VERSION ""

NS_ :

BS_:

BU_: AFC TeampoEVB TDA4VE AutoBox HMI_Simulation
VAL_TABLE_ work_mode 2 " value '0x2'  direct echoes" 1 "value '0x1'  cross echoes " 0 "value '0x0'  off " ;

BO_ 3221225472 VECTOR__INDEPENDENT_SIG_MSG: 0 Vector__XXX
 SG_ AVM_Status_Flag : 0|2@0+ (1,0) [0|3] "" Vector__XXX
 SG_ AVM_Show_Flag : 0|2@0+ (1,0) [0|3] "" Vector__XXX
 SG_ USS_RR_RRM_Dis_Valid : 0|1@0+ (1,0) [0|1] "" Vector__XXX
 SG_ USS_RR_RRM_Dis : 0|9@0+ (0.02,0) [0|10.22] "m" Vector__XXX
 SG_ USS_RRM_RR_Dis_Valid : 0|1@0+ (1,0) [0|1] "" Vector__XXX
 SG_ USS_RRM_RR_Dis : 0|9@0+ (0.02,0) [0|10.22] "m" Vector__XXX
 SG_ USS_RRM_RLM_Dis_Valid : 0|1@0+ (1,0) [0|1] "" Vector__XXX
 SG_ USS_RRM_RLM_Dis : 0|9@0+ (0.02,0) [0|10.22] "m" Vector__XXX
 SG_ USS_RLM_RRM_Dis_Valid : 0|1@0+ (1,0) [0|1] "" Vector__XXX
 SG_ USS_RLM_RRM_Dis : 0|9@0+ (0.02,0) [0|10.22] "m" Vector__XXX
 SG_ USS_RLM_RL_Dis_Valid : 0|1@0+ (1,0) [0|1] "" Vector__XXX
 SG_ USS_RLM_RL_Dis : 0|9@0+ (0.02,0) [0|10.22] "m" Vector__XXX
 SG_ USS_RL_RLM_Dis_Valid : 0|1@0+ (1,0) [0|1] "" Vector__XXX
 SG_ USS_RL_RLM_Dis : 0|9@0+ (0.02,0) [0|10.22] "m" Vector__XXX

BO_ 776 P_USS_SEN8_ADV_TR: 1 Vector__XXX
 SG_ uss8_TR : 7|8@0+ (1,0) [0|3] "" Vector__XXX

BO_ 775 P_USS_SEN7_ADV_TR: 1 Vector__XXX
 SG_ uss7_TR : 7|8@0+ (1,0) [0|3] "" Vector__XXX

BO_ 774 P_USS_SEN6_ADV_TR: 1 Vector__XXX
 SG_ uss6_TR : 7|8@0+ (1,0) [0|3] "" Vector__XXX

BO_ 773 P_USS_SEN5_ADV_TR: 1 Vector__XXX
 SG_ uss5_TR : 7|8@0+ (1,0) [0|3] "" Vector__XXX

BO_ 772 P_USS_SEN4_ADV_TR: 1 Vector__XXX
 SG_ uss4_TR : 7|8@0+ (1,0) [0|3] "" Vector__XXX

BO_ 771 P_USS_SEN3_ADV_TR: 1 Vector__XXX
 SG_ uss3_TR : 7|8@0+ (1,0) [0|3] "" Vector__XXX

BO_ 770 P_USS_SEN2_ADV_TR: 1 Vector__XXX
 SG_ uss2_TR : 7|8@0+ (1,0) [0|3] "" Vector__XXX

BO_ 769 P_USS_SEN1_ADV_TR: 1 Vector__XXX
 SG_ uss1_TR : 7|8@0+ (1,0) [0|3] "" Vector__XXX

BO_ 1360 P_USS_SEN8_ADV_A: 8 Vector__XXX
 SG_ USS_SEN8_BRC20_HEIGHTFILT : 39|16@0+ (1,0) [0|65535] "" Vector__XXX
 SG_ USS_SEN8_BRC20_DISTANCE : 55|9@0+ (0.02,0) [0|10.22] "m" Vector__XXX
 SG_ USS_SEN8_BRC20_CONFLEVEL : 62|4@0+ (1,0) [0|15] "" Vector__XXX
 SG_ USS_SEN8_BRC19_HEIGHTFILT : 7|16@0+ (1,0) [0|65535] "" Vector__XXX
 SG_ USS_SEN8_BRC19_DISTANCE : 23|9@0+ (0.02,0) [0|10.22] "m" Vector__XXX
 SG_ USS_SEN8_BRC19_CONFLEVEL : 30|4@0+ (1,0) [0|15] "" Vector__XXX

BO_ 1359 P_USS_SEN8_ADV_9: 8 Vector__XXX
 SG_ USS_SEN8_BRC18_HEIGHTFILT : 39|16@0+ (1,0) [0|65535] "" Vector__XXX
 SG_ USS_SEN8_BRC18_DISTANCE : 55|9@0+ (0.02,0) [0|10.22] "m" Vector__XXX
 SG_ USS_SEN8_BRC18_CONFLEVEL : 62|4@0+ (1,0) [0|15] "" Vector__XXX
 SG_ USS_SEN8_BRC17_HEIGHTFILT : 7|16@0+ (1,0) [0|65535] "" Vector__XXX
 SG_ USS_SEN8_BRC17_DISTANCE : 23|9@0+ (0.02,0) [0|10.22] "m" Vector__XXX
 SG_ USS_SEN8_BRC17_CONFLEVEL : 30|4@0+ (1,0) [0|15] "" Vector__XXX

BO_ 1358 P_USS_SEN8_ADV_8: 8 Vector__XXX
 SG_ USS_SEN8_BRC16_HEIGHTFILT : 39|16@0+ (1,0) [0|65535] "" Vector__XXX
 SG_ USS_SEN8_BRC16_DISTANCE : 55|9@0+ (0.02,0) [0|10.22] "m" Vector__XXX
 SG_ USS_SEN8_BRC16_CONFLEVEL : 62|4@0+ (1,0) [0|15] "" Vector__XXX
 SG_ USS_SEN8_BRC15_HEIGHTFILT : 7|16@0+ (1,0) [0|65535] "" Vector__XXX
 SG_ USS_SEN8_BRC15_DISTANCE : 23|9@0+ (0.02,0) [0|10.22] "m" Vector__XXX
 SG_ USS_SEN8_BRC15_CONFLEVEL : 30|4@0+ (1,0) [0|15] "" Vector__XXX

BO_ 1357 P_USS_SEN8_ADV_7: 8 Vector__XXX
 SG_ USS_SEN8_BRC14_HEIGHTFILT : 39|16@0+ (1,0) [0|65535] "" Vector__XXX
 SG_ USS_SEN8_BRC14_DISTANCE : 55|9@0+ (0.02,0) [0|10.22] "m" Vector__XXX
 SG_ USS_SEN8_BRC14_CONFLEVEL : 62|4@0+ (1,0) [0|15] "" Vector__XXX
 SG_ USS_SEN8_BRC13_HEIGHTFILT : 7|16@0+ (1,0) [0|65535] "" Vector__XXX
 SG_ USS_SEN8_BRC13_DISTANCE : 23|9@0+ (0.02,0) [0|10.22] "m" Vector__XXX
 SG_ USS_SEN8_BRC13_CONFLEVEL : 30|4@0+ (1,0) [0|15] "" Vector__XXX

BO_ 1356 P_USS_SEN8_ADV_6: 8 Vector__XXX
 SG_ USS_SEN8_BRC12_HEIGHTFILT : 39|16@0+ (1,0) [0|65535] "" Vector__XXX
 SG_ USS_SEN8_BRC12_DISTANCE : 55|9@0+ (0.02,0) [0|10.22] "m" Vector__XXX
 SG_ USS_SEN8_BRC12_CONFLEVEL : 62|4@0+ (1,0) [0|15] "" Vector__XXX
 SG_ USS_SEN8_BRC11_HEIGHTFILT : 7|16@0+ (1,0) [0|65535] "" Vector__XXX
 SG_ USS_SEN8_BRC11_DISTANCE : 23|9@0+ (0.02,0) [0|10.22] "m" Vector__XXX
 SG_ USS_SEN8_BRC11_CONFLEVEL : 30|4@0+ (1,0) [0|15] "" Vector__XXX

BO_ 1355 P_USS_SEN8_ADV_5: 8 Vector__XXX
 SG_ USS_SEN8_BRC10_HEIGHTFILT : 39|16@0+ (1,0) [0|65535] "" Vector__XXX
 SG_ USS_SEN8_BRC10_DISTANCE : 55|9@0+ (0.02,0) [0|10.22] "m" Vector__XXX
 SG_ USS_SEN8_BRC10_CONFLEVEL : 62|4@0+ (1,0) [0|15] "" Vector__XXX
 SG_ USS_SEN8_BRC9_HEIGHTFILT : 7|16@0+ (1,0) [0|65535] "" Vector__XXX
 SG_ USS_SEN8_BRC9_DISTANCE : 23|9@0+ (0.02,0) [0|10.22] "m" Vector__XXX
 SG_ USS_SEN8_BRC9_CONFLEVEL : 30|4@0+ (1,0) [0|15] "" Vector__XXX

BO_ 1354 P_USS_SEN8_ADV_4: 8 Vector__XXX
 SG_ USS_SEN8_BRC8_HEIGHTFILT : 39|16@0+ (1,0) [0|65535] "" Vector__XXX
 SG_ USS_SEN8_BRC8_DISTANCE : 55|9@0+ (0.02,0) [0|10.22] "m" Vector__XXX
 SG_ USS_SEN8_BRC8_CONFLEVEL : 62|4@0+ (1,0) [0|15] "" Vector__XXX
 SG_ USS_SEN8_BRC7_HEIGHTFILT : 7|16@0+ (1,0) [0|65535] "" Vector__XXX
 SG_ USS_SEN8_BRC7_DISTANCE : 23|9@0+ (0.02,0) [0|10.22] "m" Vector__XXX
 SG_ USS_SEN8_BRC7_CONFLEVEL : 30|4@0+ (1,0) [0|15] "" Vector__XXX

BO_ 1353 P_USS_SEN8_ADV_3: 8 Vector__XXX
 SG_ USS_SEN8_BRC6_HEIGHTFILT : 39|16@0+ (1,0) [0|65535] "" Vector__XXX
 SG_ USS_SEN8_BRC6_DISTANCE : 55|9@0+ (0.02,0) [0|10.22] "m" Vector__XXX
 SG_ USS_SEN8_BRC6_CONFLEVEL : 62|4@0+ (1,0) [0|15] "" Vector__XXX
 SG_ USS_SEN8_BRC5_HEIGHTFILT : 7|16@0+ (1,0) [0|65535] "" Vector__XXX
 SG_ USS_SEN8_BRC5_DISTANCE : 23|9@0+ (0.02,0) [0|10.22] "m" Vector__XXX
 SG_ USS_SEN8_BRC5_CONFLEVEL : 30|4@0+ (1,0) [0|15] "" Vector__XXX

BO_ 1352 P_USS_SEN8_ADV_2: 8 Vector__XXX
 SG_ USS_SEN8_BRC4_HEIGHTFILT : 39|16@0+ (1,0) [0|65535] "" Vector__XXX
 SG_ USS_SEN8_BRC4_DISTANCE : 55|9@0+ (0.02,0) [0|10.22] "m" Vector__XXX
 SG_ USS_SEN8_BRC4_CONFLEVEL : 62|4@0+ (1,0) [0|15] "" Vector__XXX
 SG_ USS_SEN8_BRC3_HEIGHTFILT : 7|16@0+ (1,0) [0|65535] "" Vector__XXX
 SG_ USS_SEN8_BRC3_DISTANCE : 23|9@0+ (0.02,0) [0|10.22] "m" Vector__XXX
 SG_ USS_SEN8_BRC3_CONFLEVEL : 30|4@0+ (1,0) [0|15] "" Vector__XXX

BO_ 1351 P_USS_SEN8_ADV_1: 8 Vector__XXX
 SG_ USS_SEN8_BRC2_HEIGHTFILT : 39|16@0+ (1,0) [0|65535] "" Vector__XXX
 SG_ USS_SEN8_BRC2_DISTANCE : 55|9@0+ (0.02,0) [0|10.22] "m" Vector__XXX
 SG_ USS_SEN8_BRC2_CONFLEVEL : 62|4@0+ (1,0) [0|15] "" Vector__XXX
 SG_ USS_SEN8_BRC1_HEIGHTFILT : 7|16@0+ (1,0) [0|65535] "" Vector__XXX
 SG_ USS_SEN8_BRC1_DISTANCE : 23|9@0+ (0.02,0) [0|10.22] "m" Vector__XXX
 SG_ USS_SEN8_BRC1_CONFLEVEL : 30|4@0+ (1,0) [0|15] "" Vector__XXX

BO_ 1350 P_USS_SEN7_ADV_A: 8 Vector__XXX
 SG_ USS_SEN7_BRC20_HEIGHTFILT : 39|16@0+ (1,0) [0|65535] "" Vector__XXX
 SG_ USS_SEN7_BRC20_DISTANCE : 55|9@0+ (0.02,0) [0|10.22] "m" Vector__XXX
 SG_ USS_SEN7_BRC20_CONFLEVEL : 62|4@0+ (1,0) [0|15] "" Vector__XXX
 SG_ USS_SEN7_BRC19_HEIGHTFILT : 7|16@0+ (1,0) [0|65535] "" Vector__XXX
 SG_ USS_SEN7_BRC19_DISTANCE : 23|9@0+ (0.02,0) [0|10.22] "m" Vector__XXX
 SG_ USS_SEN7_BRC19_CONFLEVEL : 30|4@0+ (1,0) [0|15] "" Vector__XXX

BO_ 1349 P_USS_SEN7_ADV_9: 8 Vector__XXX
 SG_ USS_SEN7_BRC18_HEIGHTFILT : 39|16@0+ (1,0) [0|65535] "" Vector__XXX
 SG_ USS_SEN7_BRC18_DISTANCE : 55|9@0+ (0.02,0) [0|10.22] "m" Vector__XXX
 SG_ USS_SEN7_BRC18_CONFLEVEL : 62|4@0+ (1,0) [0|15] "" Vector__XXX
 SG_ USS_SEN7_BRC17_HEIGHTFILT : 7|16@0+ (1,0) [0|65535] "" Vector__XXX
 SG_ USS_SEN7_BRC17_DISTANCE : 23|9@0+ (0.02,0) [0|10.22] "m" Vector__XXX
 SG_ USS_SEN7_BRC17_CONFLEVEL : 30|4@0+ (1,0) [0|15] "" Vector__XXX

BO_ 1348 P_USS_SEN7_ADV_8: 8 Vector__XXX
 SG_ USS_SEN7_BRC16_HEIGHTFILT : 39|16@0+ (1,0) [0|65535] "" Vector__XXX
 SG_ USS_SEN7_BRC16_DISTANCE : 55|9@0+ (0.02,0) [0|10.22] "m" Vector__XXX
 SG_ USS_SEN7_BRC16_CONFLEVEL : 62|4@0+ (1,0) [0|15] "" Vector__XXX
 SG_ USS_SEN7_BRC15_HEIGHTFILT : 7|16@0+ (1,0) [0|65535] "" Vector__XXX
 SG_ USS_SEN7_BRC15_DISTANCE : 23|9@0+ (0.02,0) [0|10.22] "m" Vector__XXX
 SG_ USS_SEN7_BRC15_CONFLEVEL : 30|4@0+ (1,0) [0|15] "" Vector__XXX

BO_ 1347 P_USS_SEN7_ADV_7: 8 Vector__XXX
 SG_ USS_SEN7_BRC14_HEIGHTFILT : 39|16@0+ (1,0) [0|65535] "" Vector__XXX
 SG_ USS_SEN7_BRC14_DISTANCE : 55|9@0+ (0.02,0) [0|10.22] "m" Vector__XXX
 SG_ USS_SEN7_BRC14_CONFLEVEL : 62|4@0+ (1,0) [0|15] "" Vector__XXX
 SG_ USS_SEN7_BRC13_HEIGHTFILT : 7|16@0+ (1,0) [0|65535] "" Vector__XXX
 SG_ USS_SEN7_BRC13_DISTANCE : 23|9@0+ (0.02,0) [0|10.22] "m" Vector__XXX
 SG_ USS_SEN7_BRC13_CONFLEVEL : 30|4@0+ (1,0) [0|15] "" Vector__XXX

BO_ 1346 P_USS_SEN7_ADV_6: 8 Vector__XXX
 SG_ USS_SEN7_BRC12_HEIGHTFILT : 39|16@0+ (1,0) [0|65535] "" Vector__XXX
 SG_ USS_SEN7_BRC12_DISTANCE : 55|9@0+ (0.02,0) [0|10.22] "m" Vector__XXX
 SG_ USS_SEN7_BRC12_CONFLEVEL : 62|4@0+ (1,0) [0|15] "" Vector__XXX
 SG_ USS_SEN7_BRC11_HEIGHTFILT : 7|16@0+ (1,0) [0|65535] "" Vector__XXX
 SG_ USS_SEN7_BRC11_DISTANCE : 23|9@0+ (0.02,0) [0|10.22] "m" Vector__XXX
 SG_ USS_SEN7_BRC11_CONFLEVEL : 30|4@0+ (1,0) [0|15] "" Vector__XXX

BO_ 1345 P_USS_SEN7_ADV_5: 8 Vector__XXX
 SG_ USS_SEN7_BRC10_HEIGHTFILT : 39|16@0+ (1,0) [0|65535] "" Vector__XXX
 SG_ USS_SEN7_BRC10_DISTANCE : 55|9@0+ (0.02,0) [0|10.22] "m" Vector__XXX
 SG_ USS_SEN7_BRC10_CONFLEVEL : 62|4@0+ (1,0) [0|15] "" Vector__XXX
 SG_ USS_SEN7_BRC9_HEIGHTFILT : 7|16@0+ (1,0) [0|65535] "" Vector__XXX
 SG_ USS_SEN7_BRC9_DISTANCE : 23|9@0+ (0.02,0) [0|10.22] "m" Vector__XXX
 SG_ USS_SEN7_BRC9_CONFLEVEL : 30|4@0+ (1,0) [0|15] "" Vector__XXX

BO_ 1344 P_USS_SEN7_ADV_4: 8 Vector__XXX
 SG_ USS_SEN7_BRC8_HEIGHTFILT : 39|16@0+ (1,0) [0|65535] "" Vector__XXX
 SG_ USS_SEN7_BRC8_DISTANCE : 55|9@0+ (0.02,0) [0|10.22] "m" Vector__XXX
 SG_ USS_SEN7_BRC8_CONFLEVEL : 62|4@0+ (1,0) [0|15] "" Vector__XXX
 SG_ USS_SEN7_BRC7_HEIGHTFILT : 7|16@0+ (1,0) [0|65535] "" Vector__XXX
 SG_ USS_SEN7_BRC7_DISTANCE : 23|9@0+ (0.02,0) [0|10.22] "m" Vector__XXX
 SG_ USS_SEN7_BRC7_CONFLEVEL : 30|4@0+ (1,0) [0|15] "" Vector__XXX

BO_ 1343 P_USS_SEN7_ADV_3: 8 Vector__XXX
 SG_ USS_SEN7_BRC6_HEIGHTFILT : 39|16@0+ (1,0) [0|65535] "" Vector__XXX
 SG_ USS_SEN7_BRC6_DISTANCE : 55|9@0+ (0.02,0) [0|10.22] "m" Vector__XXX
 SG_ USS_SEN7_BRC6_CONFLEVEL : 62|4@0+ (1,0) [0|15] "" Vector__XXX
 SG_ USS_SEN7_BRC5_HEIGHTFILT : 7|16@0+ (1,0) [0|65535] "" Vector__XXX
 SG_ USS_SEN7_BRC5_DISTANCE : 23|9@0+ (0.02,0) [0|10.22] "m" Vector__XXX
 SG_ USS_SEN7_BRC5_CONFLEVEL : 30|4@0+ (1,0) [0|15] "" Vector__XXX

BO_ 1342 P_USS_SEN7_ADV_2: 8 Vector__XXX
 SG_ USS_SEN7_BRC4_HEIGHTFILT : 39|16@0+ (1,0) [0|65535] "" Vector__XXX
 SG_ USS_SEN7_BRC4_DISTANCE : 55|9@0+ (0.02,0) [0|10.22] "m" Vector__XXX
 SG_ USS_SEN7_BRC4_CONFLEVEL : 62|4@0+ (1,0) [0|15] "" Vector__XXX
 SG_ USS_SEN7_BRC3_HEIGHTFILT : 7|16@0+ (1,0) [0|65535] "" Vector__XXX
 SG_ USS_SEN7_BRC3_DISTANCE : 23|9@0+ (0.02,0) [0|10.22] "m" Vector__XXX
 SG_ USS_SEN7_BRC3_CONFLEVEL : 30|4@0+ (1,0) [0|15] "" Vector__XXX

BO_ 1341 P_USS_SEN7_ADV_1: 8 Vector__XXX
 SG_ USS_SEN7_BRC2_HEIGHTFILT : 39|16@0+ (1,0) [0|65535] "" Vector__XXX
 SG_ USS_SEN7_BRC2_DISTANCE : 55|9@0+ (0.02,0) [0|10.22] "m" Vector__XXX
 SG_ USS_SEN7_BRC2_CONFLEVEL : 62|4@0+ (1,0) [0|15] "" Vector__XXX
 SG_ USS_SEN7_BRC1_HEIGHTFILT : 7|16@0+ (1,0) [0|65535] "" Vector__XXX
 SG_ USS_SEN7_BRC1_DISTANCE : 23|9@0+ (0.02,0) [0|10.22] "m" Vector__XXX
 SG_ USS_SEN7_BRC1_CONFLEVEL : 30|4@0+ (1,0) [0|15] "" Vector__XXX

BO_ 1340 P_USS_SEN6_ADV_A: 8 Vector__XXX
 SG_ USS_SEN6_BRC20_HEIGHTFILT : 39|16@0+ (1,0) [0|65535] "" Vector__XXX
 SG_ USS_SEN6_BRC20_DISTANCE : 55|9@0+ (0.02,0) [0|10.22] "m" Vector__XXX
 SG_ USS_SEN6_BRC20_CONFLEVEL : 62|4@0+ (1,0) [0|15] "" Vector__XXX
 SG_ USS_SEN6_BRC19_HEIGHTFILT : 7|16@0+ (1,0) [0|65535] "" Vector__XXX
 SG_ USS_SEN6_BRC19_DISTANCE : 23|9@0+ (0.02,0) [0|10.22] "m" Vector__XXX
 SG_ USS_SEN6_BRC19_CONFLEVEL : 30|4@0+ (1,0) [0|15] "" Vector__XXX

BO_ 1339 P_USS_SEN6_ADV_9: 8 Vector__XXX
 SG_ USS_SEN6_BRC18_HEIGHTFILT : 39|16@0+ (1,0) [0|65535] "" Vector__XXX
 SG_ USS_SEN6_BRC18_DISTANCE : 55|9@0+ (0.02,0) [0|10.22] "m" Vector__XXX
 SG_ USS_SEN6_BRC18_CONFLEVEL : 62|4@0+ (1,0) [0|15] "" Vector__XXX
 SG_ USS_SEN6_BRC17_HEIGHTFILT : 7|16@0+ (1,0) [0|65535] "" Vector__XXX
 SG_ USS_SEN6_BRC17_DISTANCE : 23|9@0+ (0.02,0) [0|10.22] "m" Vector__XXX
 SG_ USS_SEN6_BRC17_CONFLEVEL : 30|4@0+ (1,0) [0|15] "" Vector__XXX

BO_ 1338 P_USS_SEN6_ADV_8: 8 Vector__XXX
 SG_ USS_SEN6_BRC16_HEIGHTFILT : 39|16@0+ (1,0) [0|65535] "" Vector__XXX
 SG_ USS_SEN6_BRC16_DISTANCE : 55|9@0+ (0.02,0) [0|10.22] "m" Vector__XXX
 SG_ USS_SEN6_BRC16_CONFLEVEL : 62|4@0+ (1,0) [0|15] "" Vector__XXX
 SG_ USS_SEN6_BRC15_HEIGHTFILT : 7|16@0+ (1,0) [0|65535] "" Vector__XXX
 SG_ USS_SEN6_BRC15_DISTANCE : 23|9@0+ (0.02,0) [0|10.22] "m" Vector__XXX
 SG_ USS_SEN6_BRC15_CONFLEVEL : 30|4@0+ (1,0) [0|15] "" Vector__XXX

BO_ 1337 P_USS_SEN6_ADV_7: 8 Vector__XXX
 SG_ USS_SEN6_BRC14_HEIGHTFILT : 39|16@0+ (1,0) [0|65535] "" Vector__XXX
 SG_ USS_SEN6_BRC14_DISTANCE : 55|9@0+ (0.02,0) [0|10.22] "m" Vector__XXX
 SG_ USS_SEN6_BRC14_CONFLEVEL : 62|4@0+ (1,0) [0|15] "" Vector__XXX
 SG_ USS_SEN6_BRC13_HEIGHTFILT : 7|16@0+ (1,0) [0|65535] "" Vector__XXX
 SG_ USS_SEN6_BRC13_DISTANCE : 23|9@0+ (0.02,0) [0|10.22] "m" Vector__XXX
 SG_ USS_SEN6_BRC13_CONFLEVEL : 30|4@0+ (1,0) [0|15] "" Vector__XXX

BO_ 1336 P_USS_SEN6_ADV_6: 8 Vector__XXX
 SG_ USS_SEN6_BRC12_HEIGHTFILT : 39|16@0+ (1,0) [0|65535] "" Vector__XXX
 SG_ USS_SEN6_BRC12_DISTANCE : 55|9@0+ (0.02,0) [0|10.22] "m" Vector__XXX
 SG_ USS_SEN6_BRC12_CONFLEVEL : 62|4@0+ (1,0) [0|15] "" Vector__XXX
 SG_ USS_SEN6_BRC11_HEIGHTFILT : 7|16@0+ (1,0) [0|65535] "" Vector__XXX
 SG_ USS_SEN6_BRC11_DISTANCE : 23|9@0+ (0.02,0) [0|10.22] "m" Vector__XXX
 SG_ USS_SEN6_BRC11_CONFLEVEL : 30|4@0+ (1,0) [0|15] "" Vector__XXX

BO_ 1335 P_USS_SEN6_ADV_5: 8 Vector__XXX
 SG_ USS_SEN6_BRC10_HEIGHTFILT : 39|16@0+ (1,0) [0|65535] "" Vector__XXX
 SG_ USS_SEN6_BRC10_DISTANCE : 55|9@0+ (0.02,0) [0|10.22] "m" Vector__XXX
 SG_ USS_SEN6_BRC10_CONFLEVEL : 62|4@0+ (1,0) [0|15] "" Vector__XXX
 SG_ USS_SEN6_BRC9_HEIGHTFILT : 7|16@0+ (1,0) [0|65535] "" Vector__XXX
 SG_ USS_SEN6_BRC9_DISTANCE : 23|9@0+ (0.02,0) [0|10.22] "m" Vector__XXX
 SG_ USS_SEN6_BRC9_CONFLEVEL : 30|4@0+ (1,0) [0|15] "" Vector__XXX

BO_ 1334 P_USS_SEN6_ADV_4: 8 Vector__XXX
 SG_ USS_SEN6_BRC8_HEIGHTFILT : 39|16@0+ (1,0) [0|65535] "" Vector__XXX
 SG_ USS_SEN6_BRC8_DISTANCE : 55|9@0+ (0.02,0) [0|10.22] "m" Vector__XXX
 SG_ USS_SEN6_BRC8_CONFLEVEL : 62|4@0+ (1,0) [0|15] "" Vector__XXX
 SG_ USS_SEN6_BRC7_HEIGHTFILT : 7|16@0+ (1,0) [0|65535] "" Vector__XXX
 SG_ USS_SEN6_BRC7_DISTANCE : 23|9@0+ (0.02,0) [0|10.22] "m" Vector__XXX
 SG_ USS_SEN6_BRC7_CONFLEVEL : 30|4@0+ (1,0) [0|15] "" Vector__XXX

BO_ 1333 P_USS_SEN6_ADV_3: 8 Vector__XXX
 SG_ USS_SEN6_BRC6_HEIGHTFILT : 39|16@0+ (1,0) [0|65535] "" Vector__XXX
 SG_ USS_SEN6_BRC6_DISTANCE : 55|9@0+ (0.02,0) [0|10.22] "m" Vector__XXX
 SG_ USS_SEN6_BRC6_CONFLEVEL : 62|4@0+ (1,0) [0|15] "" Vector__XXX
 SG_ USS_SEN6_BRC5_HEIGHTFILT : 7|16@0+ (1,0) [0|65535] "" Vector__XXX
 SG_ USS_SEN6_BRC5_DISTANCE : 23|9@0+ (0.02,0) [0|10.22] "m" Vector__XXX
 SG_ USS_SEN6_BRC5_CONFLEVEL : 30|4@0+ (1,0) [0|15] "" Vector__XXX

BO_ 1332 P_USS_SEN6_ADV_2: 8 Vector__XXX
 SG_ USS_SEN6_BRC4_HEIGHTFILT : 39|16@0+ (1,0) [0|65535] "" Vector__XXX
 SG_ USS_SEN6_BRC4_DISTANCE : 55|9@0+ (0.02,0) [0|10.22] "m" Vector__XXX
 SG_ USS_SEN6_BRC4_CONFLEVEL : 62|4@0+ (1,0) [0|15] "" Vector__XXX
 SG_ USS_SEN6_BRC3_HEIGHTFILT : 7|16@0+ (1,0) [0|65535] "" Vector__XXX
 SG_ USS_SEN6_BRC3_DISTANCE : 23|9@0+ (0.02,0) [0|10.22] "m" Vector__XXX
 SG_ USS_SEN6_BRC3_CONFLEVEL : 30|4@0+ (1,0) [0|15] "" Vector__XXX

BO_ 1331 P_USS_SEN6_ADV_1: 8 Vector__XXX
 SG_ USS_SEN6_BRC2_HEIGHTFILT : 39|16@0+ (1,0) [0|65535] "" Vector__XXX
 SG_ USS_SEN6_BRC2_DISTANCE : 55|9@0+ (0.02,0) [0|10.22] "m" Vector__XXX
 SG_ USS_SEN6_BRC2_CONFLEVEL : 62|4@0+ (1,0) [0|15] "" Vector__XXX
 SG_ USS_SEN6_BRC1_HEIGHTFILT : 7|16@0+ (1,0) [0|65535] "" Vector__XXX
 SG_ USS_SEN6_BRC1_DISTANCE : 23|9@0+ (0.02,0) [0|10.22] "m" Vector__XXX
 SG_ USS_SEN6_BRC1_CONFLEVEL : 30|4@0+ (1,0) [0|15] "" Vector__XXX

BO_ 1330 P_USS_SEN5_ADV_A: 8 Vector__XXX
 SG_ USS_SEN5_BRC20_HEIGHTFILT : 39|16@0+ (1,0) [0|65535] "" Vector__XXX
 SG_ USS_SEN5_BRC20_DISTANCE : 55|9@0+ (0.02,0) [0|10.22] "m" Vector__XXX
 SG_ USS_SEN5_BRC20_CONFLEVEL : 62|4@0+ (1,0) [0|15] "" Vector__XXX
 SG_ USS_SEN5_BRC19_HEIGHTFILT : 7|16@0+ (1,0) [0|65535] "" Vector__XXX
 SG_ USS_SEN5_BRC19_DISTANCE : 23|9@0+ (0.02,0) [0|10.22] "m" Vector__XXX
 SG_ USS_SEN5_BRC19_CONFLEVEL : 30|4@0+ (1,0) [0|15] "" Vector__XXX

BO_ 1329 P_USS_SEN5_ADV_9: 8 Vector__XXX
 SG_ USS_SEN5_BRC18_HEIGHTFILT : 39|16@0+ (1,0) [0|65535] "" Vector__XXX
 SG_ USS_SEN5_BRC18_DISTANCE : 55|9@0+ (0.02,0) [0|10.22] "m" Vector__XXX
 SG_ USS_SEN5_BRC18_CONFLEVEL : 62|4@0+ (1,0) [0|15] "" Vector__XXX
 SG_ USS_SEN5_BRC17_HEIGHTFILT : 7|16@0+ (1,0) [0|65535] "" Vector__XXX
 SG_ USS_SEN5_BRC17_DISTANCE : 23|9@0+ (0.02,0) [0|10.22] "m" Vector__XXX
 SG_ USS_SEN5_BRC17_CONFLEVEL : 30|4@0+ (1,0) [0|15] "" Vector__XXX

BO_ 1328 P_USS_SEN5_ADV_8: 8 Vector__XXX
 SG_ USS_SEN5_BRC16_HEIGHTFILT : 39|16@0+ (1,0) [0|65535] "" Vector__XXX
 SG_ USS_SEN5_BRC16_DISTANCE : 55|9@0+ (0.02,0) [0|10.22] "m" Vector__XXX
 SG_ USS_SEN5_BRC16_CONFLEVEL : 62|4@0+ (1,0) [0|15] "" Vector__XXX
 SG_ USS_SEN5_BRC15_HEIGHTFILT : 7|16@0+ (1,0) [0|65535] "" Vector__XXX
 SG_ USS_SEN5_BRC15_DISTANCE : 23|9@0+ (0.02,0) [0|10.22] "m" Vector__XXX
 SG_ USS_SEN5_BRC15_CONFLEVEL : 30|4@0+ (1,0) [0|15] "" Vector__XXX

BO_ 1327 P_USS_SEN5_ADV_7: 8 Vector__XXX
 SG_ USS_SEN5_BRC14_HEIGHTFILT : 39|16@0+ (1,0) [0|65535] "" Vector__XXX
 SG_ USS_SEN5_BRC14_DISTANCE : 55|9@0+ (0.02,0) [0|10.22] "m" Vector__XXX
 SG_ USS_SEN5_BRC14_CONFLEVEL : 62|4@0+ (1,0) [0|15] "" Vector__XXX
 SG_ USS_SEN5_BRC13_HEIGHTFILT : 7|16@0+ (1,0) [0|65535] "" Vector__XXX
 SG_ USS_SEN5_BRC13_DISTANCE : 23|9@0+ (0.02,0) [0|10.22] "m" Vector__XXX
 SG_ USS_SEN5_BRC13_CONFLEVEL : 30|4@0+ (1,0) [0|15] "" Vector__XXX

BO_ 1326 P_USS_SEN5_ADV_6: 8 Vector__XXX
 SG_ USS_SEN5_BRC12_HEIGHTFILT : 39|16@0+ (1,0) [0|65535] "" Vector__XXX
 SG_ USS_SEN5_BRC12_DISTANCE : 55|9@0+ (0.02,0) [0|10.22] "m" Vector__XXX
 SG_ USS_SEN5_BRC12_CONFLEVEL : 62|4@0+ (1,0) [0|15] "" Vector__XXX
 SG_ USS_SEN5_BRC11_HEIGHTFILT : 7|16@0+ (1,0) [0|65535] "" Vector__XXX
 SG_ USS_SEN5_BRC11_DISTANCE : 23|9@0+ (0.02,0) [0|10.22] "m" Vector__XXX
 SG_ USS_SEN5_BRC11_CONFLEVEL : 30|4@0+ (1,0) [0|15] "" Vector__XXX

BO_ 1325 P_USS_SEN5_ADV_5: 8 Vector__XXX
 SG_ USS_SEN5_BRC10_HEIGHTFILT : 39|16@0+ (1,0) [0|65535] "" Vector__XXX
 SG_ USS_SEN5_BRC10_DISTANCE : 55|9@0+ (0.02,0) [0|10.22] "m" Vector__XXX
 SG_ USS_SEN5_BRC10_CONFLEVEL : 62|4@0+ (1,0) [0|15] "" Vector__XXX
 SG_ USS_SEN5_BRC9_HEIGHTFILT : 7|16@0+ (1,0) [0|65535] "" Vector__XXX
 SG_ USS_SEN5_BRC9_DISTANCE : 23|9@0+ (0.02,0) [0|10.22] "m" Vector__XXX
 SG_ USS_SEN5_BRC9_CONFLEVEL : 30|4@0+ (1,0) [0|15] "" Vector__XXX

BO_ 1324 P_USS_SEN5_ADV_4: 8 Vector__XXX
 SG_ USS_SEN5_BRC8_HEIGHTFILT : 39|16@0+ (1,0) [0|65535] "" Vector__XXX
 SG_ USS_SEN5_BRC8_DISTANCE : 55|9@0+ (0.02,0) [0|10.22] "m" Vector__XXX
 SG_ USS_SEN5_BRC8_CONFLEVEL : 62|4@0+ (1,0) [0|15] "" Vector__XXX
 SG_ USS_SEN5_BRC7_HEIGHTFILT : 7|16@0+ (1,0) [0|65535] "" Vector__XXX
 SG_ USS_SEN5_BRC7_DISTANCE : 23|9@0+ (0.02,0) [0|10.22] "m" Vector__XXX
 SG_ USS_SEN5_BRC7_CONFLEVEL : 30|4@0+ (1,0) [0|15] "" Vector__XXX

BO_ 1323 P_USS_SEN5_ADV_3: 8 Vector__XXX
 SG_ USS_SEN5_BRC6_HEIGHTFILT : 39|16@0+ (1,0) [0|65535] "" Vector__XXX
 SG_ USS_SEN5_BRC6_DISTANCE : 55|9@0+ (0.02,0) [0|10.22] "m" Vector__XXX
 SG_ USS_SEN5_BRC6_CONFLEVEL : 62|4@0+ (1,0) [0|15] "" Vector__XXX
 SG_ USS_SEN5_BRC5_HEIGHTFILT : 7|16@0+ (1,0) [0|65535] "" Vector__XXX
 SG_ USS_SEN5_BRC5_DISTANCE : 23|9@0+ (0.02,0) [0|10.22] "m" Vector__XXX
 SG_ USS_SEN5_BRC5_CONFLEVEL : 30|4@0+ (1,0) [0|15] "" Vector__XXX

BO_ 1322 P_USS_SEN5_ADV_2: 8 Vector__XXX
 SG_ USS_SEN5_BRC4_HEIGHTFILT : 39|16@0+ (1,0) [0|65535] "" Vector__XXX
 SG_ USS_SEN5_BRC4_DISTANCE : 55|9@0+ (0.02,0) [0|10.22] "m" Vector__XXX
 SG_ USS_SEN5_BRC4_CONFLEVEL : 62|4@0+ (1,0) [0|15] "" Vector__XXX
 SG_ USS_SEN5_BRC3_HEIGHTFILT : 7|16@0+ (1,0) [0|65535] "" Vector__XXX
 SG_ USS_SEN5_BRC3_DISTANCE : 23|9@0+ (0.02,0) [0|10.22] "m" Vector__XXX
 SG_ USS_SEN5_BRC3_CONFLEVEL : 30|4@0+ (1,0) [0|15] "" Vector__XXX

BO_ 1321 P_USS_SEN5_ADV_1: 8 Vector__XXX
 SG_ USS_SEN5_BRC2_HEIGHTFILT : 39|16@0+ (1,0) [0|65535] "" Vector__XXX
 SG_ USS_SEN5_BRC2_DISTANCE : 55|9@0+ (0.02,0) [0|10.22] "m" Vector__XXX
 SG_ USS_SEN5_BRC2_CONFLEVEL : 62|4@0+ (1,0) [0|15] "" Vector__XXX
 SG_ USS_SEN5_BRC1_HEIGHTFILT : 7|16@0+ (1,0) [0|65535] "" Vector__XXX
 SG_ USS_SEN5_BRC1_DISTANCE : 23|9@0+ (0.02,0) [0|10.22] "m" Vector__XXX
 SG_ USS_SEN5_BRC1_CONFLEVEL : 30|4@0+ (1,0) [0|15] "" Vector__XXX

BO_ 1313 P_USS_SEN4_ADV_3: 8 Vector__XXX
 SG_ USS_SEN4_BRC6_HEIGHTFILT : 39|16@0+ (1,0) [0|65535] "" Vector__XXX
 SG_ USS_SEN4_BRC6_DISTANCE : 55|9@0+ (0.02,0) [0|10.22] "m" Vector__XXX
 SG_ USS_SEN4_BRC6_CONFLEVEL : 62|4@0+ (1,0) [0|15] "" Vector__XXX
 SG_ USS_SEN4_BRC5_HEIGHTFILT : 7|16@0+ (1,0) [0|65535] "" Vector__XXX
 SG_ USS_SEN4_BRC5_DISTANCE : 23|9@0+ (0.02,0) [0|10.22] "m" Vector__XXX
 SG_ USS_SEN4_BRC5_CONFLEVEL : 30|4@0+ (1,0) [0|15] "" Vector__XXX

BO_ 1320 P_USS_SEN4_ADV_A: 8 Vector__XXX
 SG_ USS_SEN4_BRC20_HEIGHTFILT : 39|16@0+ (1,0) [0|65535] "" Vector__XXX
 SG_ USS_SEN4_BRC20_DISTANCE : 55|9@0+ (0.02,0) [0|10.22] "m" Vector__XXX
 SG_ USS_SEN4_BRC20_CONFLEVEL : 62|4@0+ (1,0) [0|15] "" Vector__XXX
 SG_ USS_SEN4_BRC19_HEIGHTFILT : 7|16@0+ (1,0) [0|65535] "" Vector__XXX
 SG_ USS_SEN4_BRC19_DISTANCE : 23|9@0+ (0.02,0) [0|10.22] "m" Vector__XXX
 SG_ USS_SEN4_BRC19_CONFLEVEL : 30|4@0+ (1,0) [0|15] "" Vector__XXX

BO_ 1319 P_USS_SEN4_ADV_9: 8 Vector__XXX
 SG_ USS_SEN4_BRC18_HEIGHTFILT : 39|16@0+ (1,0) [0|65535] "" Vector__XXX
 SG_ USS_SEN4_BRC18_DISTANCE : 55|9@0+ (0.02,0) [0|10.22] "m" Vector__XXX
 SG_ USS_SEN4_BRC18_CONFLEVEL : 62|4@0+ (1,0) [0|15] "" Vector__XXX
 SG_ USS_SEN4_BRC17_HEIGHTFILT : 7|16@0+ (1,0) [0|65535] "" Vector__XXX
 SG_ USS_SEN4_BRC17_DISTANCE : 23|9@0+ (0.02,0) [0|10.22] "m" Vector__XXX
 SG_ USS_SEN4_BRC17_CONFLEVEL : 30|4@0+ (1,0) [0|15] "" Vector__XXX

BO_ 1318 P_USS_SEN4_ADV_8: 8 Vector__XXX
 SG_ USS_SEN4_BRC16_HEIGHTFILT : 39|16@0+ (1,0) [0|65535] "" Vector__XXX
 SG_ USS_SEN4_BRC16_DISTANCE : 55|9@0+ (0.02,0) [0|10.22] "m" Vector__XXX
 SG_ USS_SEN4_BRC16_CONFLEVEL : 62|4@0+ (1,0) [0|15] "" Vector__XXX
 SG_ USS_SEN4_BRC15_HEIGHTFILT : 7|16@0+ (1,0) [0|65535] "" Vector__XXX
 SG_ USS_SEN4_BRC15_DISTANCE : 23|9@0+ (0.02,0) [0|10.22] "m" Vector__XXX
 SG_ USS_SEN4_BRC15_CONFLEVEL : 30|4@0+ (1,0) [0|15] "" Vector__XXX

BO_ 1317 P_USS_SEN4_ADV_7: 8 Vector__XXX
 SG_ USS_SEN4_BRC14_HEIGHTFILT : 39|16@0+ (1,0) [0|65535] "" Vector__XXX
 SG_ USS_SEN4_BRC14_DISTANCE : 55|9@0+ (0.02,0) [0|10.22] "m" Vector__XXX
 SG_ USS_SEN4_BRC14_CONFLEVEL : 62|4@0+ (1,0) [0|15] "" Vector__XXX
 SG_ USS_SEN4_BRC13_HEIGHTFILT : 7|16@0+ (1,0) [0|65535] "" Vector__XXX
 SG_ USS_SEN4_BRC13_DISTANCE : 23|9@0+ (0.02,0) [0|10.22] "m" Vector__XXX
 SG_ USS_SEN4_BRC13_CONFLEVEL : 30|4@0+ (1,0) [0|15] "" Vector__XXX

BO_ 1316 P_USS_SEN4_ADV_6: 8 Vector__XXX
 SG_ USS_SEN4_BRC12_HEIGHTFILT : 39|16@0+ (1,0) [0|65535] "" Vector__XXX
 SG_ USS_SEN4_BRC12_DISTANCE : 55|9@0+ (0.02,0) [0|10.22] "m" Vector__XXX
 SG_ USS_SEN4_BRC12_CONFLEVEL : 62|4@0+ (1,0) [0|15] "" Vector__XXX
 SG_ USS_SEN4_BRC11_HEIGHTFILT : 7|16@0+ (1,0) [0|65535] "" Vector__XXX
 SG_ USS_SEN4_BRC11_DISTANCE : 23|9@0+ (0.02,0) [0|10.22] "m" Vector__XXX
 SG_ USS_SEN4_BRC11_CONFLEVEL : 30|4@0+ (1,0) [0|15] "" Vector__XXX

BO_ 1315 P_USS_SEN4_ADV_5: 8 Vector__XXX
 SG_ USS_SEN4_BRC10_HEIGHTFILT : 39|16@0+ (1,0) [0|65535] "" Vector__XXX
 SG_ USS_SEN4_BRC10_DISTANCE : 55|9@0+ (0.02,0) [0|10.22] "m" Vector__XXX
 SG_ USS_SEN4_BRC10_CONFLEVEL : 62|4@0+ (1,0) [0|15] "" Vector__XXX
 SG_ USS_SEN4_BRC9_HEIGHTFILT : 7|16@0+ (1,0) [0|65535] "" Vector__XXX
 SG_ USS_SEN4_BRC9_DISTANCE : 23|9@0+ (0.02,0) [0|10.22] "m" Vector__XXX
 SG_ USS_SEN4_BRC9_CONFLEVEL : 30|4@0+ (1,0) [0|15] "" Vector__XXX

BO_ 1314 P_USS_SEN4_ADV_4: 8 Vector__XXX
 SG_ USS_SEN4_BRC8_HEIGHTFILT : 39|16@0+ (1,0) [0|65535] "" Vector__XXX
 SG_ USS_SEN4_BRC8_DISTANCE : 55|9@0+ (0.02,0) [0|10.22] "m" Vector__XXX
 SG_ USS_SEN4_BRC8_CONFLEVEL : 62|4@0+ (1,0) [0|15] "" Vector__XXX
 SG_ USS_SEN4_BRC7_HEIGHTFILT : 7|16@0+ (1,0) [0|65535] "" Vector__XXX
 SG_ USS_SEN4_BRC7_DISTANCE : 23|9@0+ (0.02,0) [0|10.22] "m" Vector__XXX
 SG_ USS_SEN4_BRC7_CONFLEVEL : 30|4@0+ (1,0) [0|15] "" Vector__XXX

BO_ 1312 P_USS_SEN4_ADV_2: 8 Vector__XXX
 SG_ USS_SEN4_BRC4_HEIGHTFILT : 39|16@0+ (1,0) [0|65535] "" Vector__XXX
 SG_ USS_SEN4_BRC4_DISTANCE : 55|9@0+ (0.02,0) [0|10.22] "m" Vector__XXX
 SG_ USS_SEN4_BRC4_CONFLEVEL : 62|4@0+ (1,0) [0|15] "" Vector__XXX
 SG_ USS_SEN4_BRC3_HEIGHTFILT : 7|16@0+ (1,0) [0|65535] "" Vector__XXX
 SG_ USS_SEN4_BRC3_DISTANCE : 23|9@0+ (0.02,0) [0|10.22] "m" Vector__XXX
 SG_ USS_SEN4_BRC3_CONFLEVEL : 30|4@0+ (1,0) [0|15] "" Vector__XXX

BO_ 1311 P_USS_SEN4_ADV_1: 8 Vector__XXX
 SG_ USS_SEN4_BRC2_HEIGHTFILT : 39|16@0+ (1,0) [0|65535] "" Vector__XXX
 SG_ USS_SEN4_BRC2_DISTANCE : 55|9@0+ (0.02,0) [0|10.22] "m" Vector__XXX
 SG_ USS_SEN4_BRC2_CONFLEVEL : 62|4@0+ (1,0) [0|15] "" Vector__XXX
 SG_ USS_SEN4_BRC1_HEIGHTFILT : 7|16@0+ (1,0) [0|65535] "" Vector__XXX
 SG_ USS_SEN4_BRC1_DISTANCE : 23|9@0+ (0.02,0) [0|10.22] "m" Vector__XXX
 SG_ USS_SEN4_BRC1_CONFLEVEL : 30|4@0+ (1,0) [0|15] "" Vector__XXX

BO_ 1310 P_USS_SEN3_ADV_A: 8 Vector__XXX
 SG_ USS_SEN3_BRC20_HEIGHTFILT : 39|16@0+ (1,0) [0|65535] "" Vector__XXX
 SG_ USS_SEN3_BRC20_DISTANCE : 55|9@0+ (0.02,0) [0|10.22] "m" Vector__XXX
 SG_ USS_SEN3_BRC20_CONFLEVEL : 62|4@0+ (1,0) [0|15] "" Vector__XXX
 SG_ USS_SEN3_BRC19_HEIGHTFILT : 7|16@0+ (1,0) [0|65535] "" Vector__XXX
 SG_ USS_SEN3_BRC19_DISTANCE : 23|9@0+ (0.02,0) [0|10.22] "m" Vector__XXX
 SG_ USS_SEN3_BRC19_CONFLEVEL : 30|4@0+ (1,0) [0|15] "" Vector__XXX

BO_ 1309 P_USS_SEN3_ADV_9: 8 Vector__XXX
 SG_ USS_SEN3_BRC18_HEIGHTFILT : 39|16@0+ (1,0) [0|65535] "" Vector__XXX
 SG_ USS_SEN3_BRC18_DISTANCE : 55|9@0+ (0.02,0) [0|10.22] "m" Vector__XXX
 SG_ USS_SEN3_BRC18_CONFLEVEL : 62|4@0+ (1,0) [0|15] "" Vector__XXX
 SG_ USS_SEN3_BRC17_HEIGHTFILT : 7|16@0+ (1,0) [0|65535] "" Vector__XXX
 SG_ USS_SEN3_BRC17_DISTANCE : 23|9@0+ (0.02,0) [0|10.22] "m" Vector__XXX
 SG_ USS_SEN3_BRC17_CONFLEVEL : 30|4@0+ (1,0) [0|15] "" Vector__XXX

BO_ 1308 P_USS_SEN3_ADV_8: 8 Vector__XXX
 SG_ USS_SEN3_BRC16_HEIGHTFILT : 39|16@0+ (1,0) [0|65535] "" Vector__XXX
 SG_ USS_SEN3_BRC16_DISTANCE : 55|9@0+ (0.02,0) [0|10.22] "m" Vector__XXX
 SG_ USS_SEN3_BRC16_CONFLEVEL : 62|4@0+ (1,0) [0|15] "" Vector__XXX
 SG_ USS_SEN3_BRC15_HEIGHTFILT : 7|16@0+ (1,0) [0|65535] "" Vector__XXX
 SG_ USS_SEN3_BRC15_DISTANCE : 23|9@0+ (0.02,0) [0|10.22] "m" Vector__XXX
 SG_ USS_SEN3_BRC15_CONFLEVEL : 30|4@0+ (1,0) [0|15] "" Vector__XXX

BO_ 1307 P_USS_SEN3_ADV_7: 8 Vector__XXX
 SG_ USS_SEN3_BRC14_HEIGHTFILT : 39|16@0+ (1,0) [0|65535] "" Vector__XXX
 SG_ USS_SEN3_BRC14_DISTANCE : 55|9@0+ (0.02,0) [0|10.22] "m" Vector__XXX
 SG_ USS_SEN3_BRC14_CONFLEVEL : 62|4@0+ (1,0) [0|15] "" Vector__XXX
 SG_ USS_SEN3_BRC13_HEIGHTFILT : 7|16@0+ (1,0) [0|65535] "" Vector__XXX
 SG_ USS_SEN3_BRC13_DISTANCE : 23|9@0+ (0.02,0) [0|10.22] "m" Vector__XXX
 SG_ USS_SEN3_BRC13_CONFLEVEL : 30|4@0+ (1,0) [0|15] "" Vector__XXX

BO_ 1306 P_USS_SEN3_ADV_6: 8 Vector__XXX
 SG_ USS_SEN3_BRC12_HEIGHTFILT : 39|16@0+ (1,0) [0|65535] "" Vector__XXX
 SG_ USS_SEN3_BRC12_DISTANCE : 55|9@0+ (0.02,0) [0|10.22] "m" Vector__XXX
 SG_ USS_SEN3_BRC12_CONFLEVEL : 62|4@0+ (1,0) [0|15] "" Vector__XXX
 SG_ USS_SEN3_BRC11_HEIGHTFILT : 7|16@0+ (1,0) [0|65535] "" Vector__XXX
 SG_ USS_SEN3_BRC11_DISTANCE : 23|9@0+ (0.02,0) [0|10.22] "m" Vector__XXX
 SG_ USS_SEN3_BRC11_CONFLEVEL : 30|4@0+ (1,0) [0|15] "" Vector__XXX

BO_ 1305 P_USS_SEN3_ADV_5: 8 Vector__XXX
 SG_ USS_SEN3_BRC10_DISTANCE : 55|9@0+ (0.02,0) [0|10.22] "m" Vector__XXX
 SG_ USS_SEN3_BRC10_CONFLEVEL : 62|4@0+ (1,0) [0|15] "" Vector__XXX
 SG_ USS_SEN3_BRC10_HEIGHTFILT : 39|16@0+ (1,0) [0|65535] "" Vector__XXX
 SG_ USS_SEN3_BRC9_CONFLEVEL : 30|4@0+ (1,0) [0|15] "" Vector__XXX
 SG_ USS_SEN3_BRC9_DISTANCE : 23|9@0+ (0.02,0) [0|10.22] "m" Vector__XXX
 SG_ USS_SEN3_BRC9_HEIGHTFILT : 7|16@0+ (1,0) [0|65535] "" Vector__XXX

BO_ 1304 P_USS_SEN3_ADV_4: 8 Vector__XXX
 SG_ USS_SEN3_BRC8_CONFLEVEL : 62|4@0+ (1,0) [0|15] "" Vector__XXX
 SG_ USS_SEN3_BRC8_DISTANCE : 55|9@0+ (0.02,0) [0|10.22] "m" Vector__XXX
 SG_ USS_SEN3_BRC8_HEIGHTFILT : 39|16@0+ (1,0) [0|65535] "" Vector__XXX
 SG_ USS_SEN3_BRC7_CONFLEVEL : 30|4@0+ (1,0) [0|15] "" Vector__XXX
 SG_ USS_SEN3_BRC7_DISTANCE : 23|9@0+ (0.02,0) [0|10.22] "m" Vector__XXX
 SG_ USS_SEN3_BRC7_HEIGHTFILT : 7|16@0+ (1,0) [0|65535] "" Vector__XXX

BO_ 1303 P_USS_SEN3_ADV_3: 8 Vector__XXX
 SG_ USS_SEN3_BRC6_CONFLEVEL : 62|4@0+ (1,0) [0|15] "" Vector__XXX
 SG_ USS_SEN3_BRC6_DISTANCE : 55|9@0+ (0.02,0) [0|10.22] "m" Vector__XXX
 SG_ USS_SEN3_BRC6_HEIGHTFILT : 39|16@0+ (1,0) [0|65535] "" Vector__XXX
 SG_ USS_SEN3_BRC5_CONFLEVEL : 30|4@0+ (1,0) [0|15] "" Vector__XXX
 SG_ USS_SEN3_BRC5_DISTANCE : 23|9@0+ (0.02,0) [0|10.22] "m" Vector__XXX
 SG_ USS_SEN3_BRC5_HEIGHTFILT : 7|16@0+ (1,0) [0|65535] "" Vector__XXX

BO_ 1302 P_USS_SEN3_ADV_2: 8 Vector__XXX
 SG_ USS_SEN3_BRC4_CONFLEVEL : 62|4@0+ (1,0) [0|15] "" Vector__XXX
 SG_ USS_SEN3_BRC4_DISTANCE : 55|9@0+ (0.02,0) [0|10.22] "m" Vector__XXX
 SG_ USS_SEN3_BRC4_HEIGHTFILT : 39|16@0+ (1,0) [0|65535] "" Vector__XXX
 SG_ USS_SEN3_BRC3_CONFLEVEL : 30|4@0+ (1,0) [0|15] "" Vector__XXX
 SG_ USS_SEN3_BRC3_DISTANCE : 23|9@0+ (0.02,0) [0|10.22] "m" Vector__XXX
 SG_ USS_SEN3_BRC3_HEIGHTFILT : 7|16@0+ (1,0) [0|65535] "" Vector__XXX

BO_ 1301 P_USS_SEN3_ADV_1: 8 Vector__XXX
 SG_ USS_SEN3_BRC2_CONFLEVEL : 62|4@0+ (1,0) [0|15] "" Vector__XXX
 SG_ USS_SEN3_BRC2_DISTANCE : 55|9@0+ (0.02,0) [0|10.22] "m" Vector__XXX
 SG_ USS_SEN3_BRC2_HEIGHTFILT : 39|16@0+ (1,0) [0|65535] "" Vector__XXX
 SG_ USS_SEN3_BRC1_CONFLEVEL : 30|4@0+ (1,0) [0|15] "" Vector__XXX
 SG_ USS_SEN3_BRC1_DISTANCE : 23|9@0+ (0.02,0) [0|10.22] "m" Vector__XXX
 SG_ USS_SEN3_BRC1_HEIGHTFILT : 7|16@0+ (1,0) [0|65535] "" Vector__XXX

BO_ 1300 P_USS_SEN2_ADV_A: 8 Vector__XXX
 SG_ USS_SEN2_BRC20_CONFLEVEL : 62|4@0+ (1,0) [0|15] "" Vector__XXX
 SG_ USS_SEN2_BRC20_DISTANCE : 55|9@0+ (0.02,0) [0|10.22] "m" Vector__XXX
 SG_ USS_SEN2_BRC20_HEIGHTFILT : 39|16@0+ (1,0) [0|65535] "" Vector__XXX
 SG_ USS_SEN2_BRC19_CONFLEVEL : 30|4@0+ (1,0) [0|15] "" Vector__XXX
 SG_ USS_SEN2_BRC19_DISTANCE : 23|9@0+ (0.02,0) [0|10.22] "m" Vector__XXX
 SG_ USS_SEN2_BRC19_HEIGHTFILT : 7|16@0+ (1,0) [0|65535] "" Vector__XXX

BO_ 1299 P_USS_SEN2_ADV_9: 8 Vector__XXX
 SG_ USS_SEN2_BRC17_CONFLEVEL : 30|4@0+ (1,0) [0|15] "" Vector__XXX
 SG_ USS_SEN2_BRC17_DISTANCE : 23|9@0+ (0.02,0) [0|10.22] "m" Vector__XXX
 SG_ USS_SEN2_BRC17_HEIGHTFILT : 7|16@0+ (1,0) [0|65535] "" Vector__XXX
 SG_ USS_SEN2_BRC18_CONFLEVEL : 62|4@0+ (1,0) [0|15] "" Vector__XXX
 SG_ USS_SEN2_BRC18_DISTANCE : 55|9@0+ (0.02,0) [0|10.22] "m" Vector__XXX
 SG_ USS_SEN2_BRC18_HEIGHTFILT : 39|16@0+ (1,0) [0|65535] "" Vector__XXX

BO_ 1298 P_USS_SEN2_ADV_8: 8 Vector__XXX
 SG_ USS_SEN2_BRC15_CONFLEVEL : 30|4@0+ (1,0) [0|15] "" Vector__XXX
 SG_ USS_SEN2_BRC15_DISTANCE : 23|9@0+ (0.02,0) [0|10.22] "m" Vector__XXX
 SG_ USS_SEN2_BRC15_HEIGHTFILT : 7|16@0+ (1,0) [0|65535] "" Vector__XXX
 SG_ USS_SEN2_BRC16_CONFLEVEL : 62|4@0+ (1,0) [0|15] "" Vector__XXX
 SG_ USS_SEN2_BRC16_DISTANCE : 55|9@0+ (0.02,0) [0|10.22] "m" Vector__XXX
 SG_ USS_SEN2_BRC16_HEIGHTFILT : 39|16@0+ (1,0) [0|65535] "" Vector__XXX

BO_ 1297 P_USS_SEN2_ADV_7: 8 Vector__XXX
 SG_ USS_SEN2_BRC13_CONFLEVEL : 30|4@0+ (1,0) [0|15] "" Vector__XXX
 SG_ USS_SEN2_BRC13_DISTANCE : 23|9@0+ (0.02,0) [0|10.22] "m" Vector__XXX
 SG_ USS_SEN2_BRC13_HEIGHTFILT : 7|16@0+ (1,0) [0|65535] "" Vector__XXX
 SG_ USS_SEN2_BRC14_CONFLEVEL : 62|4@0+ (1,0) [0|15] "" Vector__XXX
 SG_ USS_SEN2_BRC14_DISTANCE : 55|9@0+ (0.02,0) [0|10.22] "m" Vector__XXX
 SG_ USS_SEN2_BRC14_HEIGHTFILT : 39|16@0+ (1,0) [0|65535] "" Vector__XXX

BO_ 1296 P_USS_SEN2_ADV_6: 8 Vector__XXX
 SG_ USS_SEN2_BRC11_CONFLEVEL : 30|4@0+ (1,0) [0|15] "" Vector__XXX
 SG_ USS_SEN2_BRC11_DISTANCE : 23|9@0+ (0.02,0) [0|10.22] "m" Vector__XXX
 SG_ USS_SEN2_BRC11_HEIGHTFILT : 7|16@0+ (1,0) [0|65535] "" Vector__XXX
 SG_ USS_SEN2_BRC12_CONFLEVEL : 62|4@0+ (1,0) [0|15] "" Vector__XXX
 SG_ USS_SEN2_BRC12_DISTANCE : 55|9@0+ (0.02,0) [0|10.22] "m" Vector__XXX
 SG_ USS_SEN2_BRC12_HEIGHTFILT : 39|16@0+ (1,0) [0|65535] "" Vector__XXX

BO_ 1295 P_USS_SEN2_ADV_5: 8 Vector__XXX
 SG_ USS_SEN2_BRC9_CONFLEVEL : 30|4@0+ (1,0) [0|15] "" Vector__XXX
 SG_ USS_SEN2_BRC9_DISTANCE : 23|9@0+ (0.02,0) [0|10.22] "m" Vector__XXX
 SG_ USS_SEN2_BRC9_HEIGHTFILT : 7|16@0+ (1,0) [0|65535] "" Vector__XXX
 SG_ USS_SEN2_BRC10_CONFLEVEL : 62|4@0+ (1,0) [0|15] "" Vector__XXX
 SG_ USS_SEN2_BRC10_DISTANCE : 55|9@0+ (0.02,0) [0|10.22] "m" Vector__XXX
 SG_ USS_SEN2_BRC10_HEIGHTFILT : 39|16@0+ (1,0) [0|65535] "" Vector__XXX

BO_ 1294 P_USS_SEN2_ADV_4: 8 Vector__XXX
 SG_ USS_SEN2_BRC8_CONFLEVEL : 62|4@0+ (1,0) [0|15] "" Vector__XXX
 SG_ USS_SEN2_BRC8_DISTANCE : 55|9@0+ (0.02,0) [0|10.22] "m" Vector__XXX
 SG_ USS_SEN2_BRC8_HEIGHTFILT : 39|16@0+ (1,0) [0|65535] "" Vector__XXX
 SG_ USS_SEN2_BRC7_CONFLEVEL : 30|4@0+ (1,0) [0|15] "" Vector__XXX
 SG_ USS_SEN2_BRC7_DISTANCE : 23|9@0+ (0.02,0) [0|10.22] "m" Vector__XXX
 SG_ USS_SEN2_BRC7_HEIGHTFILT : 7|16@0+ (1,0) [0|65535] "" Vector__XXX

BO_ 1293 P_USS_SEN2_ADV_3: 8 Vector__XXX
 SG_ USS_SEN2_BRC6_CONFLEVEL : 62|4@0+ (1,0) [0|15] "" Vector__XXX
 SG_ USS_SEN2_BRC6_DISTANCE : 55|9@0+ (0.02,0) [0|10.22] "m" Vector__XXX
 SG_ USS_SEN2_BRC6_HEIGHTFILT : 39|16@0+ (1,0) [0|65535] "" Vector__XXX
 SG_ USS_SEN2_BRC5_CONFLEVEL : 30|4@0+ (1,0) [0|15] "" Vector__XXX
 SG_ USS_SEN2_BRC5_DISTANCE : 23|9@0+ (0.02,0) [0|10.22] "m" Vector__XXX
 SG_ USS_SEN2_BRC5_HEIGHTFILT : 7|16@0+ (1,0) [0|65535] "" Vector__XXX

BO_ 1292 P_USS_SEN2_ADV_2: 8 Vector__XXX
 SG_ USS_SEN2_BRC4_CONFLEVEL : 62|4@0+ (1,0) [0|15] "" Vector__XXX
 SG_ USS_SEN2_BRC4_DISTANCE : 55|9@0+ (0.02,0) [0|10.22] "m" Vector__XXX
 SG_ USS_SEN2_BRC4_HEIGHTFILT : 39|16@0+ (1,0) [0|65535] "" Vector__XXX
 SG_ USS_SEN2_BRC3_CONFLEVEL : 30|4@0+ (1,0) [0|15] "" Vector__XXX
 SG_ USS_SEN2_BRC3_DISTANCE : 23|9@0+ (0.02,0) [0|10.22] "m" Vector__XXX
 SG_ USS_SEN2_BRC3_HEIGHTFILT : 7|16@0+ (1,0) [0|65535] "" Vector__XXX

BO_ 1291 P_USS_SEN2_ADV_1: 8 Vector__XXX
 SG_ USS_SEN2_BRC2_CONFLEVEL : 62|4@0+ (1,0) [0|15] "" Vector__XXX
 SG_ USS_SEN2_BRC2_DISTANCE : 55|9@0+ (0.02,0) [0|10.22] "m" Vector__XXX
 SG_ USS_SEN2_BRC2_HEIGHTFILT : 39|16@0+ (1,0) [0|65535] "" Vector__XXX
 SG_ USS_SEN2_BRC1_CONFLEVEL : 30|4@0+ (1,0) [0|15] "" Vector__XXX
 SG_ USS_SEN2_BRC1_DISTANCE : 23|9@0+ (0.02,0) [0|10.22] "m" Vector__XXX
 SG_ USS_SEN2_BRC1_HEIGHTFILT : 7|16@0+ (1,0) [0|65535] "" Vector__XXX

BO_ 1290 P_USS_SEN1_ADV_A: 8 Vector__XXX
 SG_ USS_SEN1_BRC20_CONFLEVEL : 62|4@0+ (1,0) [0|15] "" Vector__XXX
 SG_ USS_SEN1_BRC20_DISTANCE : 55|9@0+ (0.02,0) [0|10.22] "" Vector__XXX
 SG_ USS_SEN1_BRC20_HEIGHTFILT : 39|16@0+ (1,0) [0|65535] "" Vector__XXX
 SG_ USS_SEN1_BRC19_CONFLEVEL : 30|4@0+ (1,0) [0|15] "" Vector__XXX
 SG_ USS_SEN1_BRC19_DISTANCE : 23|9@0+ (0.02,0) [0|10.22] "" Vector__XXX
 SG_ USS_SEN1_BRC19_HEIGHTFILT : 7|16@0+ (1,0) [0|65535] "" Vector__XXX

BO_ 1289 P_USS_SEN1_ADV_9: 8 Vector__XXX
 SG_ USS_SEN1_BRC18_CONFLEVEL : 62|4@0+ (1,0) [0|15] "" Vector__XXX
 SG_ USS_SEN1_BRC18_DISTANCE : 55|9@0+ (0.02,0) [0|10.22] "" Vector__XXX
 SG_ USS_SEN1_BRC18_HEIGHTFILT : 39|16@0+ (1,0) [0|65535] "" Vector__XXX
 SG_ USS_SEN1_BRC17_CONFLEVEL : 30|4@0+ (1,0) [0|15] "" Vector__XXX
 SG_ USS_SEN1_BRC17_DISTANCE : 23|9@0+ (0.02,0) [0|10.22] "" Vector__XXX
 SG_ USS_SEN1_BRC17_HEIGHTFILT : 7|16@0+ (1,0) [0|65535] "" Vector__XXX

BO_ 1288 P_USS_SEN1_ADV_8: 8 Vector__XXX
 SG_ USS_SEN1_BRC16_CONFLEVEL : 62|4@0+ (1,0) [0|15] "" Vector__XXX
 SG_ USS_SEN1_BRC16_DISTANCE : 55|9@0+ (0.02,0) [0|10.22] "" Vector__XXX
 SG_ USS_SEN1_BRC16_HEIGHTFILT : 39|16@0+ (1,0) [0|65535] "" Vector__XXX
 SG_ USS_SEN1_BRC15_CONFLEVEL : 30|4@0+ (1,0) [0|15] "" Vector__XXX
 SG_ USS_SEN1_BRC15_DISTANCE : 23|9@0+ (0.02,0) [0|10.22] "" Vector__XXX
 SG_ USS_SEN1_BRC15_HEIGHTFILT : 7|16@0+ (1,0) [0|65535] "" Vector__XXX

BO_ 1287 P_USS_SEN1_ADV_7: 8 Vector__XXX
 SG_ USS_SEN1_BRC14_CONFLEVEL : 62|4@0+ (1,0) [0|15] "" Vector__XXX
 SG_ USS_SEN1_BRC14_DISTANCE : 55|9@0+ (0.02,0) [0|10.22] "" Vector__XXX
 SG_ USS_SEN1_BRC14_HEIGHTFILT : 39|16@0+ (1,0) [0|65535] "" Vector__XXX
 SG_ USS_SEN1_BRC13_CONFLEVEL : 30|4@0+ (1,0) [0|15] "" Vector__XXX
 SG_ USS_SEN1_BRC13_DISTANCE : 23|9@0+ (0.02,0) [0|10.22] "" Vector__XXX
 SG_ USS_SEN1_BRC13_HEIGHTFILT : 7|16@0+ (1,0) [0|65535] "" Vector__XXX

BO_ 1286 P_USS_SEN1_ADV_6: 8 Vector__XXX
 SG_ USS_SEN1_BRC12_CONFLEVEL : 62|4@0+ (1,0) [0|15] "" Vector__XXX
 SG_ USS_SEN1_BRC12_DISTANCE : 55|9@0+ (0.02,0) [0|10.22] "" Vector__XXX
 SG_ USS_SEN1_BRC12_HEIGHTFILT : 39|16@0+ (1,0) [0|65535] "" Vector__XXX
 SG_ USS_SEN1_BRC11_CONFLEVEL : 30|4@0+ (1,0) [0|15] "" Vector__XXX
 SG_ USS_SEN1_BRC11_DISTANCE : 23|9@0+ (0.02,0) [0|10.22] "" Vector__XXX
 SG_ USS_SEN1_BRC11_HEIGHTFILT : 7|16@0+ (1,0) [0|65535] "" Vector__XXX

BO_ 1284 P_USS_SEN1_ADV_4: 8 Vector__XXX
 SG_ USS_SEN1_BRC8_CONFLEVEL : 62|4@0+ (1,0) [0|15] "" Vector__XXX
 SG_ USS_SEN1_BRC8_DISTANCE : 55|9@0+ (0.02,0) [0|10.22] "" Vector__XXX
 SG_ USS_SEN1_BRC8_HEIGHTFILT : 39|16@0+ (1,0) [0|65535] "" Vector__XXX
 SG_ USS_SEN1_BRC7_CONFLEVEL : 30|4@0+ (1,0) [0|15] "" Vector__XXX
 SG_ USS_SEN1_BRC7_DISTANCE : 23|9@0+ (0.02,0) [0|10.22] "" Vector__XXX
 SG_ USS_SEN1_BRC7_HEIGHTFILT : 7|16@0+ (1,0) [0|65535] "" Vector__XXX

BO_ 1285 P_USS_SEN1_ADV_5: 8 Vector__XXX
 SG_ USS_SEN1_BRC10_CONFLEVEL : 62|4@0+ (1,0) [0|15] "" Vector__XXX
 SG_ USS_SEN1_BRC10_DISTANCE : 55|9@0+ (0.02,0) [0|10.22] "" Vector__XXX
 SG_ USS_SEN1_BRC10_HEIGHTFILT : 39|16@0+ (1,0) [0|65535] "" Vector__XXX
 SG_ USS_SEN1_BRC9_CONFLEVEL : 30|4@0+ (1,0) [0|15] "" Vector__XXX
 SG_ USS_SEN1_BRC9_DISTANCE : 23|9@0+ (0.02,0) [0|10.22] "" Vector__XXX
 SG_ USS_SEN1_BRC9_HEIGHTFILT : 7|16@0+ (1,0) [0|65535] "" Vector__XXX

BO_ 1283 P_USS_SEN1_ADV_3: 8 Vector__XXX
 SG_ USS_SEN1_BRC6_CONFLEVEL : 62|4@0+ (1,0) [0|15] "" Vector__XXX
 SG_ USS_SEN1_BRC6_DISTANCE : 55|9@0+ (0.02,0) [0|10.22] "" Vector__XXX
 SG_ USS_SEN1_BRC6_HEIGHTFILT : 39|16@0+ (1,0) [0|65535] "" Vector__XXX
 SG_ USS_SEN1_BRC5_CONFLEVEL : 30|4@0+ (1,0) [0|15] "" Vector__XXX
 SG_ USS_SEN1_BRC5_DISTANCE : 23|9@0+ (0.02,0) [0|10.22] "" Vector__XXX
 SG_ USS_SEN1_BRC5_HEIGHTFILT : 7|16@0+ (1,0) [0|65535] "" Vector__XXX

BO_ 1282 P_USS_SEN1_ADV_2: 8 Vector__XXX
 SG_ USS_SEN1_BRC4_CONFLEVEL : 62|4@0+ (1,0) [0|15] "" Vector__XXX
 SG_ USS_SEN1_BRC4_DISTANCE : 55|9@0+ (0.02,0) [0|10.22] "" Vector__XXX
 SG_ USS_SEN1_BRC4_HEIGHTFILT : 39|16@0+ (1,0) [0|65535] "" Vector__XXX
 SG_ USS_SEN1_BRC3_CONFLEVEL : 30|4@0+ (1,0) [0|15] "" Vector__XXX
 SG_ USS_SEN1_BRC3_DISTANCE : 23|9@0+ (0.02,0) [0|10.22] "" Vector__XXX
 SG_ USS_SEN1_BRC3_HEIGHTFILT : 7|16@0+ (1,0) [0|65535] "" Vector__XXX

BO_ 1281 P_USS_SEN1_ADV_1: 8 Vector__XXX
 SG_ USS_SEN1_BRC2_DISTANCE : 55|9@0+ (0.02,0) [0|10.22] "" Vector__XXX
 SG_ USS_SEN1_BRC2_HEIGHTFILT : 39|16@0+ (1,0) [0|65535] "" Vector__XXX
 SG_ USS_SEN1_BRC2_CONFLEVEL : 62|4@0+ (1,0) [0|15] "" Vector__XXX
 SG_ USS_SEN1_BRC1_CONFLEVEL : 30|4@0+ (1,0) [0|15] "" Vector__XXX
 SG_ USS_SEN1_BRC1_DISTANCE : 23|9@0+ (0.02,0) [0|10.22] "m" Vector__XXX
 SG_ USS_SEN1_BRC1_HEIGHTFILT : 7|16@0+ (1,0) [0|65535] "" Vector__XXX

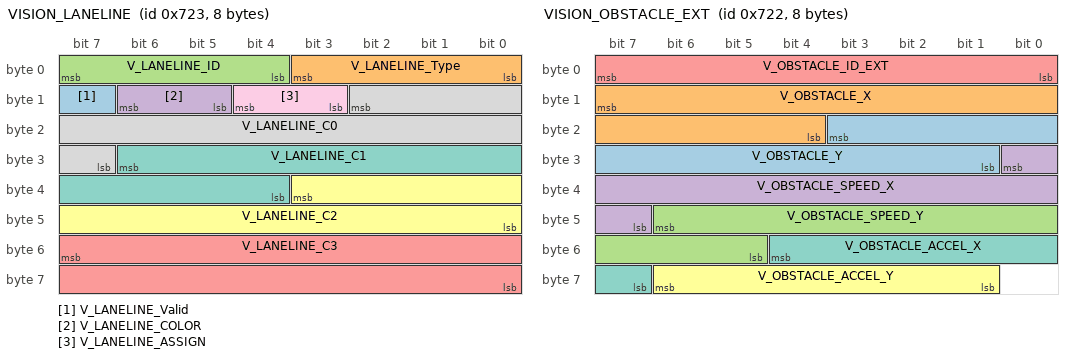
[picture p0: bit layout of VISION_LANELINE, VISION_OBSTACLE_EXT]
BO_ 1827 VISION_LANELINE: 8 TDA4VE
 SG_ V_LANELINE_Valid : 15|1@0+ (1,0) [0|1] ""  AFC
 SG_ V_LANELINE_Type : 3|4@0+ (1,0) [0|15] ""  AFC
 SG_ V_LANELINE_ID : 7|4@0+ (1,0) [0|15] ""  AFC
 SG_ V_LANELINE_COLOR : 14|2@0+ (1,0) [0|3] ""  AFC
 SG_ V_LANELINE_C3 : 55|16@0+ (1E-008,-0.00016667) [-0.00016667|0.00016667] ""  AFC
 SG_ V_LANELINE_C2 : 35|12@0+ (5E-006,-0.01) [-0.01|0.01] ""  AFC
 SG_ V_LANELINE_C1 : 30|11@0+ (0.0009,-0.9) [-0.9|0.9] ""  AFC
 SG_ V_LANELINE_C0 : 10|12@0+ (0.01,-16) [-16|15.99] ""  AFC
 SG_ V_LANELINE_ASSIGN : 12|2@0+ (1,0) [0|3] ""  AFC

BO_ 1826 VISION_OBSTACLE_EXT: 8 TDA4VE
 SG_ V_OBSTACLE_Y : 19|11@0+ (0.1,-102.4) [-102.4|102.3] "m"  AFC
 SG_ V_OBSTACLE_X : 15|12@0+ (0.1,-204.8) [-204.8|204.7] "m"  AFC
 SG_ V_OBSTACLE_SPEED_Y : 46|10@0+ (0.1,-51.2) [-51.2|51.1] "m/s"  AFC
 SG_ V_OBSTACLE_SPEED_X : 24|10@0+ (0.1,-51.2) [-51.2|51.1] "m/s"  AFC
 SG_ V_OBSTACLE_ID_EXT : 7|8@0+ (1,0) [0|255] ""  AFC
 SG_ V_OBSTACLE_ACCEL_Y : 62|6@0+ (0.1,-3.2) [-3.2|3.1] "m/s^2"  AFC
 SG_ V_OBSTACLE_ACCEL_X : 52|6@0+ (0.1,-3.2) [-3.2|3.1] "m/s^2"  AFC

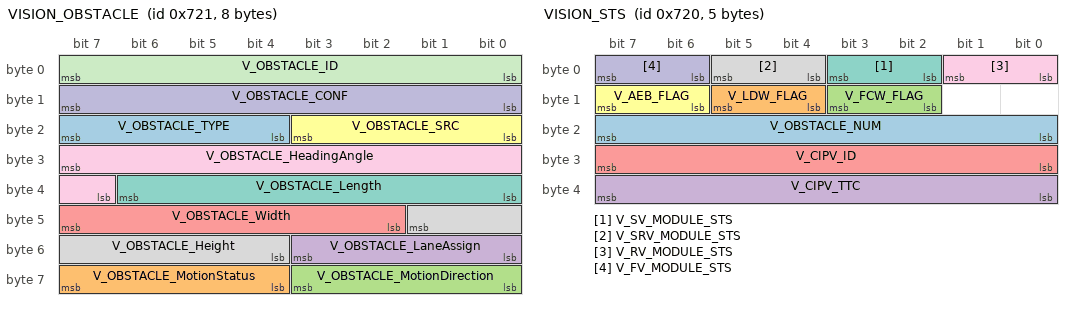
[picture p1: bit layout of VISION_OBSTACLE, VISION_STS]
BO_ 1825 VISION_OBSTACLE: 8 TDA4VE
 SG_ V_OBSTACLE_TYPE : 23|4@0+ (1,0) [0|15] ""  AFC
 SG_ V_OBSTACLE_MotionStatus : 63|4@0+ (1,0) [0|15] ""  AFC
 SG_ V_OBSTACLE_MotionDirection : 59|4@0+ (1,0) [0|15] ""  AFC
 SG_ V_OBSTACLE_LaneAssign : 51|4@0+ (1,0) [0|15] ""  AFC
 SG_ V_OBSTACLE_Width : 47|6@0+ (0.1,0) [0|6.3] "m"  AFC
 SG_ V_OBSTACLE_SRC : 19|4@0+ (1,0) [0|15] ""  AFC
 SG_ V_OBSTACLE_Length : 38|7@0+ (0.1,0) [0|12.7] "m"  AFC
 SG_ V_OBSTACLE_Height : 41|6@0+ (0.1,0) [0|6.3] "m"  AFC
 SG_ V_OBSTACLE_HeadingAngle : 31|9@0+ (1,-256) [-256|255] "deg"  AFC
 SG_ V_OBSTACLE_CONF : 15|8@0+ (0.5,0) [0|100] ""  AFC
 SG_ V_OBSTACLE_ID : 7|8@0+ (1,0) [0|255] ""  AFC

BO_ 1824 VISION_STS: 5 TDA4VE
 SG_ V_OBSTACLE_NUM : 23|8@0+ (1,0) [0|255] ""  AFC
 SG_ V_LDW_FLAG : 13|2@0+ (1,0) [0|3] ""  AFC
 SG_ V_FCW_FLAG : 11|2@0+ (1,0) [0|3] ""  AFC
 SG_ V_CIPV_TTC : 39|8@0+ (0.02,0) [0|5.1] "s"  AFC
 SG_ V_CIPV_ID : 31|8@0+ (1,0) [0|255] ""  AFC
 SG_ V_AEB_FLAG : 15|2@0+ (1,0) [0|3] ""  AFC
 SG_ V_SV_MODULE_STS : 3|2@0+ (1,0) [0|3] ""  AFC
 SG_ V_SRV_MODULE_STS : 5|2@0+ (1,0) [0|3] ""  AFC
 SG_ V_RV_MODULE_STS : 1|2@0+ (1,0) [0|3] ""  AFC
 SG_ V_FV_MODULE_STS : 7|2@0+ (1,0) [0|3] ""  AFC

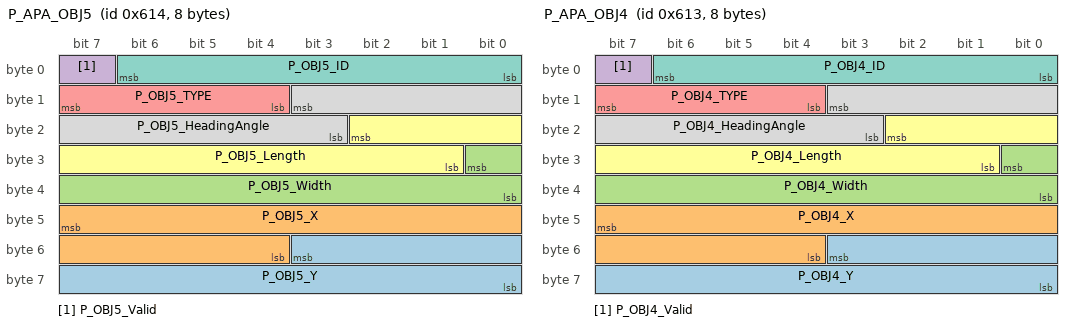
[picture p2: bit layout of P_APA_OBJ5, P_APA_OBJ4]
BO_ 1556 P_APA_OBJ5: 8 TDA4VE
 SG_ P_OBJ5_Y : 51|12@0+ (0.01,-20.48) [-20.48|20.47] "m"  AutoBox
 SG_ P_OBJ5_X : 47|12@0+ (0.01,-20.48) [-20.48|20.47] "m"  AutoBox
 SG_ P_OBJ5_Width : 24|9@0+ (0.01,0) [0|6.3] "m"  AutoBox
 SG_ P_OBJ5_Valid : 7|1@0+ (1,0) [0|1] ""  AutoBox
 SG_ P_OBJ5_TYPE : 15|4@0+ (1,0) [0|15] ""  AutoBox
 SG_ P_OBJ5_Length : 18|10@0+ (0.01,0) [0|10.23] "m"  AutoBox
 SG_ P_OBJ5_ID : 6|7@0+ (1,0) [0|127] ""  AutoBox
 SG_ P_OBJ5_HeadingAngle : 11|9@0+ (1,-256) [-256|255] "deg"  AutoBox

BO_ 1555 P_APA_OBJ4: 8 TDA4VE
 SG_ P_OBJ4_Y : 51|12@0+ (0.01,-20.48) [-20.48|20.47] "m"  AutoBox
 SG_ P_OBJ4_X : 47|12@0+ (0.01,-20.48) [-20.48|20.47] "m"  AutoBox
 SG_ P_OBJ4_Width : 24|9@0+ (0.01,0) [0|6.3] "m"  AutoBox
 SG_ P_OBJ4_Valid : 7|1@0+ (1,0) [0|1] ""  AutoBox
 SG_ P_OBJ4_TYPE : 15|4@0+ (1,0) [0|15] ""  AutoBox
 SG_ P_OBJ4_Length : 18|10@0+ (0.01,0) [0|10.23] "m"  AutoBox
 SG_ P_OBJ4_ID : 6|7@0+ (1,0) [0|127] ""  AutoBox
 SG_ P_OBJ4_HeadingAngle : 11|9@0+ (1,-256) [-256|255] "deg"  AutoBox

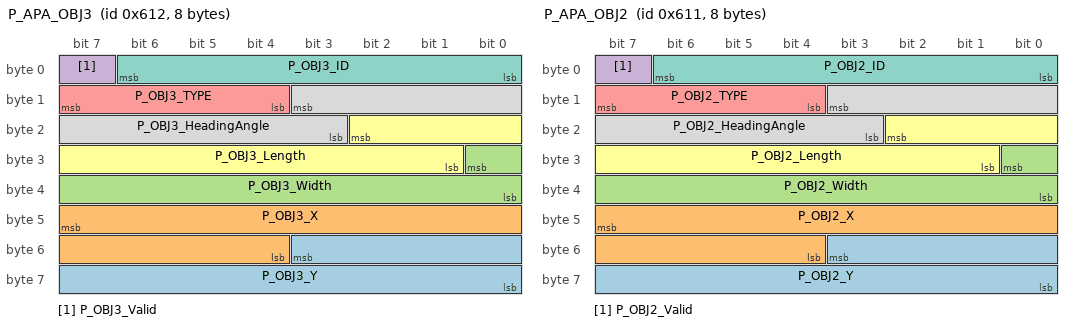
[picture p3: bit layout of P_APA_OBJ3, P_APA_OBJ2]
BO_ 1554 P_APA_OBJ3: 8 TDA4VE
 SG_ P_OBJ3_Y : 51|12@0+ (0.01,-20.48) [-20.48|20.47] "m"  AutoBox
 SG_ P_OBJ3_X : 47|12@0+ (0.01,-20.48) [-20.48|20.47] "m"  AutoBox
 SG_ P_OBJ3_Width : 24|9@0+ (0.01,0) [0|6.3] "m"  AutoBox
 SG_ P_OBJ3_Valid : 7|1@0+ (1,0) [0|1] ""  AutoBox
 SG_ P_OBJ3_TYPE : 15|4@0+ (1,0) [0|15] ""  AutoBox
 SG_ P_OBJ3_Length : 18|10@0+ (0.01,0) [0|10.23] "m"  AutoBox
 SG_ P_OBJ3_ID : 6|7@0+ (1,0) [0|127] ""  AutoBox
 SG_ P_OBJ3_HeadingAngle : 11|9@0+ (1,-256) [-256|255] "deg"  AutoBox

BO_ 1553 P_APA_OBJ2: 8 TDA4VE
 SG_ P_OBJ2_Y : 51|12@0+ (0.01,-20.48) [-20.48|20.47] "m"  AutoBox
 SG_ P_OBJ2_X : 47|12@0+ (0.01,-20.48) [-20.48|20.47] "m"  AutoBox
 SG_ P_OBJ2_Width : 24|9@0+ (0.01,0) [0|6.3] "m"  AutoBox
 SG_ P_OBJ2_Valid : 7|1@0+ (1,0) [0|1] ""  AutoBox
 SG_ P_OBJ2_TYPE : 15|4@0+ (1,0) [0|15] ""  AutoBox
 SG_ P_OBJ2_Length : 18|10@0+ (0.01,0) [0|10.23] "m"  AutoBox
 SG_ P_OBJ2_ID : 6|7@0+ (1,0) [0|127] ""  AutoBox
 SG_ P_OBJ2_HeadingAngle : 11|9@0+ (1,-256) [-256|255] "deg"  AutoBox

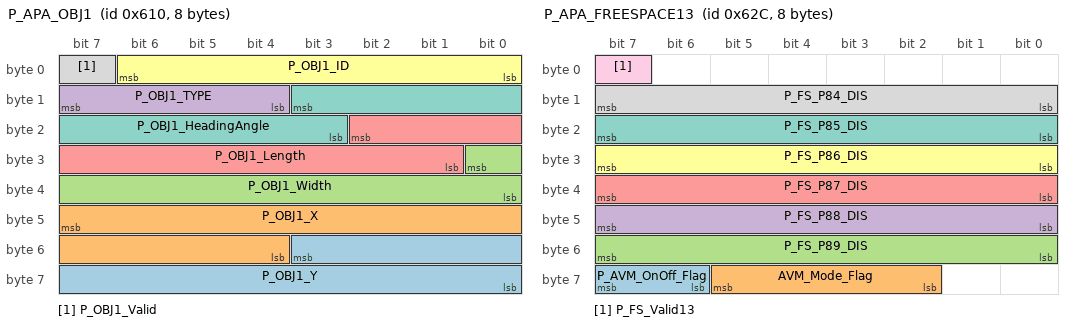
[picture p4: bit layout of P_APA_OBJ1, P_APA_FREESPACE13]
BO_ 1552 P_APA_OBJ1: 8 TDA4VE
 SG_ P_OBJ1_Y : 51|12@0+ (0.01,-20.48) [-20.48|20.47] "m"  AutoBox
 SG_ P_OBJ1_X : 47|12@0+ (0.01,-20.48) [-20.48|20.47] "m"  AutoBox
 SG_ P_OBJ1_Width : 24|9@0+ (0.01,0) [0|6.3] "m"  AutoBox
 SG_ P_OBJ1_TYPE : 15|4@0+ (1,0) [0|15] ""  AutoBox
 SG_ P_OBJ1_Length : 18|10@0+ (0.01,0) [0|10.23] "m"  AutoBox
 SG_ P_OBJ1_ID : 6|7@0+ (1,0) [0|127] ""  AutoBox
 SG_ P_OBJ1_HeadingAngle : 11|9@0+ (1,-256) [-256|255] "deg"  AutoBox
 SG_ P_OBJ1_Valid : 7|1@0+ (1,0) [0|1] ""  AutoBox

BO_ 1580 P_APA_FREESPACE13: 8 TDA4VE
 SG_ P_AVM_OnOff_Flag : 63|2@0+ (1,0) [0|3] "" Vector__XXX
 SG_ AVM_Mode_Flag : 61|4@0+ (1,0) [0|15] "" Vector__XXX
 SG_ P_FS_P89_DIS : 55|8@0+ (0.05,0) [0|12.75] "m"  AutoBox
 SG_ P_FS_P88_DIS : 47|8@0+ (0.05,0) [0|12.75] "m"  AutoBox
 SG_ P_FS_P87_DIS : 39|8@0+ (0.05,0) [0|12.75] "m"  AutoBox
 SG_ P_FS_P86_DIS : 31|8@0+ (0.05,0) [0|12.75] "m"  AutoBox
 SG_ P_FS_P85_DIS : 23|8@0+ (0.05,0) [0|12.75] "m"  AutoBox
 SG_ P_FS_P84_DIS : 15|8@0+ (0.05,0) [0|12.75] "m"  AutoBox
 SG_ P_FS_Valid13 : 7|1@0+ (1,0) [0|1] ""  AutoBox

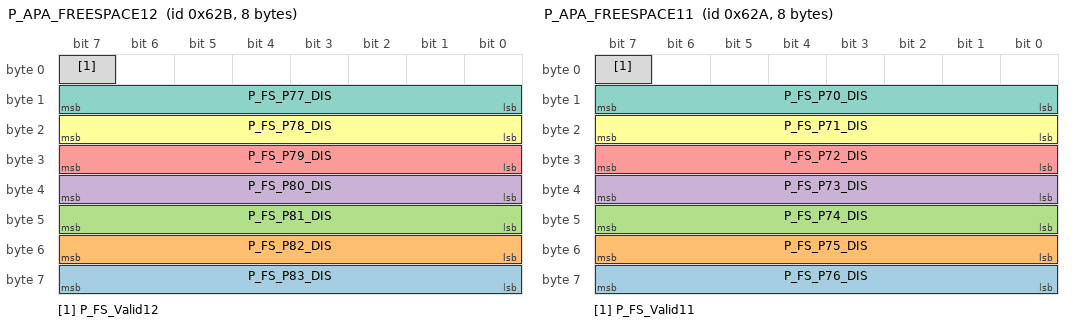
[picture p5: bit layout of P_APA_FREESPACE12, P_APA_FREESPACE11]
BO_ 1579 P_APA_FREESPACE12: 8 TDA4VE
 SG_ P_FS_P83_DIS : 63|8@0+ (0.05,0) [0|12.75] "m"  AutoBox
 SG_ P_FS_P82_DIS : 55|8@0+ (0.05,0) [0|12.75] "m"  AutoBox
 SG_ P_FS_P81_DIS : 47|8@0+ (0.05,0) [0|12.75] "m"  AutoBox
 SG_ P_FS_P80_DIS : 39|8@0+ (0.05,0) [0|12.75] "m"  AutoBox
 SG_ P_FS_P79_DIS : 31|8@0+ (0.05,0) [0|12.75] "m"  AutoBox
 SG_ P_FS_P78_DIS : 23|8@0+ (0.05,0) [0|12.75] "m"  AutoBox
 SG_ P_FS_P77_DIS : 15|8@0+ (0.05,0) [0|12.75] "m"  AutoBox
 SG_ P_FS_Valid12 : 7|1@0+ (1,0) [0|1] ""  AutoBox

BO_ 1578 P_APA_FREESPACE11: 8 TDA4VE
 SG_ P_FS_P76_DIS : 63|8@0+ (0.05,0) [0|12.75] "m"  AutoBox
 SG_ P_FS_P75_DIS : 55|8@0+ (0.05,0) [0|12.75] "m"  AutoBox
 SG_ P_FS_P74_DIS : 47|8@0+ (0.05,0) [0|12.75] "m"  AutoBox
 SG_ P_FS_P73_DIS : 39|8@0+ (0.05,0) [0|12.75] "m"  AutoBox
 SG_ P_FS_P72_DIS : 31|8@0+ (0.05,0) [0|12.75] "m"  AutoBox
 SG_ P_FS_P71_DIS : 23|8@0+ (0.05,0) [0|12.75] "m"  AutoBox
 SG_ P_FS_P70_DIS : 15|8@0+ (0.05,0) [0|12.75] "m"  AutoBox
 SG_ P_FS_Valid11 : 7|1@0+ (1,0) [0|1] ""  AutoBox

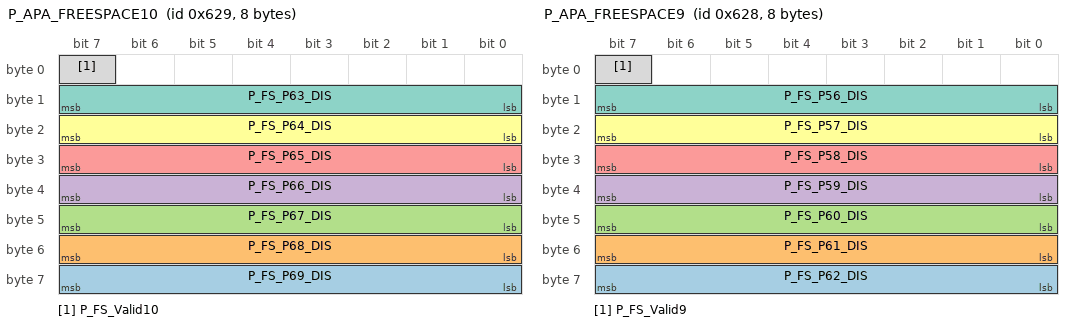
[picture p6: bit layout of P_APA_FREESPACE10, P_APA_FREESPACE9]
BO_ 1577 P_APA_FREESPACE10: 8 TDA4VE
 SG_ P_FS_P69_DIS : 63|8@0+ (0.05,0) [0|12.75] "m"  AutoBox
 SG_ P_FS_P68_DIS : 55|8@0+ (0.05,0) [0|12.75] "m"  AutoBox
 SG_ P_FS_P67_DIS : 47|8@0+ (0.05,0) [0|12.75] "m"  AutoBox
 SG_ P_FS_P66_DIS : 39|8@0+ (0.05,0) [0|12.75] "m"  AutoBox
 SG_ P_FS_P65_DIS : 31|8@0+ (0.05,0) [0|12.75] "m"  AutoBox
 SG_ P_FS_P64_DIS : 23|8@0+ (0.05,0) [0|12.75] "m"  AutoBox
 SG_ P_FS_P63_DIS : 15|8@0+ (0.05,0) [0|12.75] "m"  AutoBox
 SG_ P_FS_Valid10 : 7|1@0+ (1,0) [0|1] ""  AutoBox

BO_ 1576 P_APA_FREESPACE9: 8 TDA4VE
 SG_ P_FS_P62_DIS : 63|8@0+ (0.05,0) [0|12.75] "m"  AutoBox
 SG_ P_FS_P61_DIS : 55|8@0+ (0.05,0) [0|12.75] "m"  AutoBox
 SG_ P_FS_P60_DIS : 47|8@0+ (0.05,0) [0|12.75] "m"  AutoBox
 SG_ P_FS_P59_DIS : 39|8@0+ (0.05,0) [0|12.75] "m"  AutoBox
 SG_ P_FS_P58_DIS : 31|8@0+ (0.05,0) [0|12.75] "m"  AutoBox
 SG_ P_FS_P57_DIS : 23|8@0+ (0.05,0) [0|12.75] "m"  AutoBox
 SG_ P_FS_P56_DIS : 15|8@0+ (0.05,0) [0|12.75] "m"  AutoBox
 SG_ P_FS_Valid9 : 7|1@0+ (1,0) [0|1] ""  AutoBox

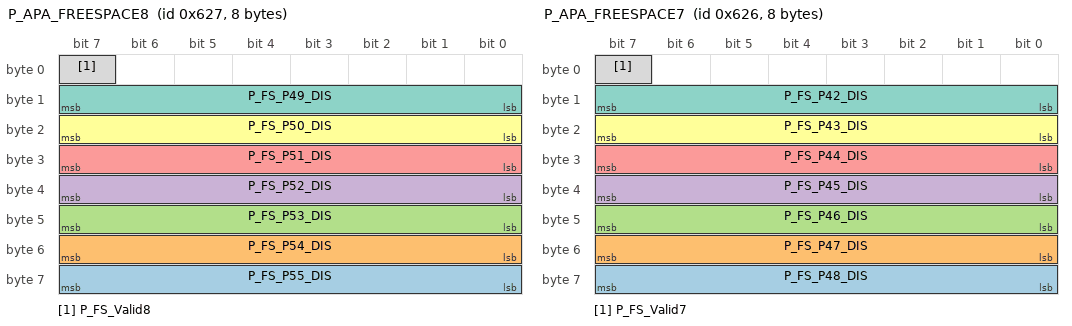
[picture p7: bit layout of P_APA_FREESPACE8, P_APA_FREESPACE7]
BO_ 1575 P_APA_FREESPACE8: 8 TDA4VE
 SG_ P_FS_P55_DIS : 63|8@0+ (0.05,0) [0|12.75] "m"  AutoBox
 SG_ P_FS_P54_DIS : 55|8@0+ (0.05,0) [0|12.75] "m"  AutoBox
 SG_ P_FS_P53_DIS : 47|8@0+ (0.05,0) [0|12.75] "m"  AutoBox
 SG_ P_FS_P52_DIS : 39|8@0+ (0.05,0) [0|12.75] "m"  AutoBox
 SG_ P_FS_P51_DIS : 31|8@0+ (0.05,0) [0|12.75] "m"  AutoBox
 SG_ P_FS_P50_DIS : 23|8@0+ (0.05,0) [0|12.75] "m"  AutoBox
 SG_ P_FS_P49_DIS : 15|8@0+ (0.05,0) [0|12.75] "m"  AutoBox
 SG_ P_FS_Valid8 : 7|1@0+ (1,0) [0|1] ""  AutoBox

BO_ 1574 P_APA_FREESPACE7: 8 TDA4VE
 SG_ P_FS_P48_DIS : 63|8@0+ (0.05,0) [0|12.75] "m"  AutoBox
 SG_ P_FS_P47_DIS : 55|8@0+ (0.05,0) [0|12.75] "m"  AutoBox
 SG_ P_FS_P46_DIS : 47|8@0+ (0.05,0) [0|12.75] "m"  AutoBox
 SG_ P_FS_P45_DIS : 39|8@0+ (0.05,0) [0|12.75] "m"  AutoBox
 SG_ P_FS_P44_DIS : 31|8@0+ (0.05,0) [0|12.75] "m"  AutoBox
 SG_ P_FS_P43_DIS : 23|8@0+ (0.05,0) [0|12.75] "m"  AutoBox
 SG_ P_FS_P42_DIS : 15|8@0+ (0.05,0) [0|12.75] "m"  AutoBox
 SG_ P_FS_Valid7 : 7|1@0+ (1,0) [0|1] ""  AutoBox

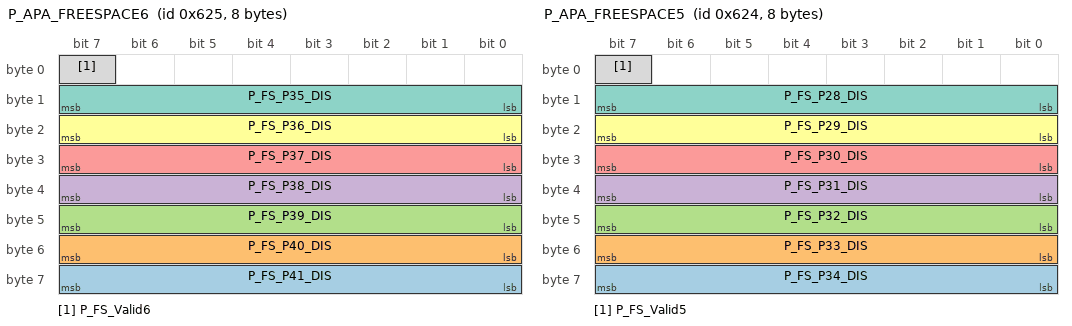
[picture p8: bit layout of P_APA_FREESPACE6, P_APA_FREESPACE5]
BO_ 1573 P_APA_FREESPACE6: 8 TDA4VE
 SG_ P_FS_P41_DIS : 63|8@0+ (0.05,0) [0|12.75] "m"  AutoBox
 SG_ P_FS_P40_DIS : 55|8@0+ (0.05,0) [0|12.75] "m"  AutoBox
 SG_ P_FS_P39_DIS : 47|8@0+ (0.05,0) [0|12.75] "m"  AutoBox
 SG_ P_FS_P38_DIS : 39|8@0+ (0.05,0) [0|12.75] "m"  AutoBox
 SG_ P_FS_P37_DIS : 31|8@0+ (0.05,0) [0|12.75] "m"  AutoBox
 SG_ P_FS_P36_DIS : 23|8@0+ (0.05,0) [0|12.75] "m"  AutoBox
 SG_ P_FS_P35_DIS : 15|8@0+ (0.05,0) [0|12.75] "m"  AutoBox
 SG_ P_FS_Valid6 : 7|1@0+ (1,0) [0|1] ""  AutoBox

BO_ 1572 P_APA_FREESPACE5: 8 TDA4VE
 SG_ P_FS_P34_DIS : 63|8@0+ (0.05,0) [0|12.75] "m"  AutoBox
 SG_ P_FS_P33_DIS : 55|8@0+ (0.05,0) [0|12.75] "m"  AutoBox
 SG_ P_FS_P32_DIS : 47|8@0+ (0.05,0) [0|12.75] "m"  AutoBox
 SG_ P_FS_P31_DIS : 39|8@0+ (0.05,0) [0|12.75] "m"  AutoBox
 SG_ P_FS_P30_DIS : 31|8@0+ (0.05,0) [0|12.75] "m"  AutoBox
 SG_ P_FS_P29_DIS : 23|8@0+ (0.05,0) [0|12.75] "m"  AutoBox
 SG_ P_FS_P28_DIS : 15|8@0+ (0.05,0) [0|12.75] "m"  AutoBox
 SG_ P_FS_Valid5 : 7|1@0+ (1,0) [0|1] ""  AutoBox

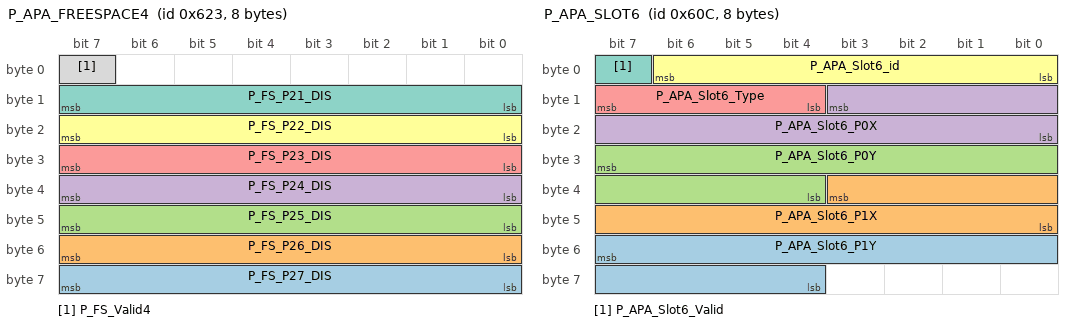
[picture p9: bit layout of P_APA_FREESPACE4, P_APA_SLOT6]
BO_ 1571 P_APA_FREESPACE4: 8 TDA4VE
 SG_ P_FS_P27_DIS : 63|8@0+ (0.05,0) [0|12.75] "m"  AutoBox
 SG_ P_FS_P26_DIS : 55|8@0+ (0.05,0) [0|12.75] "m"  AutoBox
 SG_ P_FS_P25_DIS : 47|8@0+ (0.05,0) [0|12.75] "m"  AutoBox
 SG_ P_FS_P24_DIS : 39|8@0+ (0.05,0) [0|12.75] "m"  AutoBox
 SG_ P_FS_P23_DIS : 31|8@0+ (0.05,0) [0|12.75] "m"  AutoBox
 SG_ P_FS_P22_DIS : 23|8@0+ (0.05,0) [0|12.75] "m"  AutoBox
 SG_ P_FS_P21_DIS : 15|8@0+ (0.05,0) [0|12.75] "m"  AutoBox
 SG_ P_FS_Valid4 : 7|1@0+ (1,0) [0|1] ""  AutoBox

BO_ 1570 P_APA_FREESPACE3: 8 TDA4VE
 SG_ P_FS_P20_DIS : 63|8@0+ (0.05,0) [0|12.75] "m"  AutoBox
 SG_ P_FS_P19_DIS : 55|8@0+ (0.05,0) [0|12.75] "m"  AutoBox
 SG_ P_FS_P18_DIS : 47|8@0+ (0.05,0) [0|12.75] "m"  AutoBox
 SG_ P_FS_P17_DIS : 39|8@0+ (0.05,0) [0|12.75] "m"  AutoBox
 SG_ P_FS_P16_DIS : 31|8@0+ (0.05,0) [0|12.75] "m"  AutoBox
 SG_ P_FS_P15_DIS : 23|8@0+ (0.05,0) [0|12.75] "m"  AutoBox
 SG_ P_FS_P14_DIS : 15|8@0+ (0.05,0) [0|12.75] "m"  AutoBox
 SG_ P_FS_Valid3 : 7|1@0+ (1,0) [0|1] ""  AutoBox

BO_ 1569 P_APA_FREESPACE2: 8 TDA4VE
 SG_ P_FS_P9_DIS : 31|8@0+ (0.05,0) [0|12.75] "m"  AutoBox
 SG_ P_FS_P8_DIS : 23|8@0+ (0.05,0) [0|12.75] "m"  AutoBox
 SG_ P_FS_P7_DIS : 15|8@0+ (0.05,0) [0|12.75] "m"  AutoBox
 SG_ P_FS_P13_DIS : 63|8@0+ (0.05,0) [0|12.75] "m"  AutoBox
 SG_ P_FS_P12_DIS : 55|8@0+ (0.05,0) [0|12.75] "m"  AutoBox
 SG_ P_FS_P11_DIS : 47|8@0+ (0.05,0) [0|12.75] "m"  AutoBox
 SG_ P_FS_P10_DIS : 39|8@0+ (0.05,0) [0|12.75] "m"  AutoBox
 SG_ P_FS_Valid2 : 7|1@0+ (1,0) [0|1] ""  AutoBox

BO_ 1568 P_APA_FREESPACE1: 8 TDA4VE
 SG_ P_FS_P6_DIS : 63|8@0+ (0.05,0) [0|12.75] "m"  AutoBox
 SG_ P_FS_P5_DIS : 55|8@0+ (0.05,0) [0|12.75] "m"  AutoBox
 SG_ P_FS_P4_DIS : 47|8@0+ (0.05,0) [0|12.75] "m"  AutoBox
 SG_ P_FS_P3_DIS : 39|8@0+ (0.05,0) [0|12.75] "m"  AutoBox
 SG_ P_FS_P2_DIS : 31|8@0+ (0.05,0) [0|12.75] "m"  AutoBox
 SG_ P_FS_P1_DIS : 23|8@0+ (0.05,0) [0|12.75] "m"  AutoBox
 SG_ P_FS_P0_DIS : 15|8@0+ (0.05,0) [0|12.75] "m"  AutoBox
 SG_ P_FS_Valid1 : 7|1@0+ (1,0) [0|1] ""  AutoBox

BO_ 1549 P_APA_SLOT6_EXT1: 8 TDA4VE
 SG_ P_APA_Slot6_P3Y : 43|12@0+ (0.01,-20.48) [-20.48|20.47] "m"  AutoBox
 SG_ P_APA_Slot6_P3X : 39|12@0+ (0.01,-20.48) [-20.48|20.47] "m"  AutoBox
 SG_ P_APA_Slot6_P2Y : 19|12@0+ (0.01,-20.48) [-20.48|20.47] "m"  AutoBox
 SG_ P_APA_Slot6_P2X : 15|12@0+ (0.01,-20.48) [-20.48|20.47] "m"  AutoBox
 SG_ P_APA_Slot6_Conti1 : 7|1@0+ (1,0) [0|1] ""  AutoBox

BO_ 1548 P_APA_SLOT6: 8 TDA4VE
 SG_ P_APA_Slot6_P1Y : 55|12@0+ (0.01,-20.48) [-20.48|20.47] "m"  AutoBox
 SG_ P_APA_Slot6_P1X : 35|12@0+ (0.01,-20.48) [-20.48|20.47] "m"  AutoBox
 SG_ P_APA_Slot6_P0Y : 31|12@0+ (0.01,-20.48) [-20.48|20.47] "m"  AutoBox
 SG_ P_APA_Slot6_P0X : 11|12@0+ (0.01,-20.48) [-20.48|20.47] "m"  AutoBox
 SG_ P_APA_Slot6_Type : 15|4@0+ (1,0) [0|15] ""  AutoBox
 SG_ P_APA_Slot6_id : 6|7@0+ (1,0) [0|127] ""  AutoBox
 SG_ P_APA_Slot6_Valid : 7|1@0+ (1,0) [0|1] ""  AutoBox

BO_ 1547 P_APA_SLOT5_EXT1: 8 TDA4VE
 SG_ P_APA_Slot5_P3Y : 43|12@0+ (0.01,-20.48) [-20.48|20.47] "m"  AutoBox
 SG_ P_APA_Slot5_P3X : 39|12@0+ (0.01,-20.48) [-20.48|20.47] "m"  AutoBox
 SG_ P_APA_Slot5_P2Y : 19|12@0+ (0.01,-20.48) [-20.48|20.47] "m"  AutoBox
 SG_ P_APA_Slot5_P2X : 15|12@0+ (0.01,-20.48) [-20.48|20.47] "m"  AutoBox
 SG_ P_APA_Slot5_Conti1 : 7|1@0+ (1,0) [0|1] ""  AutoBox

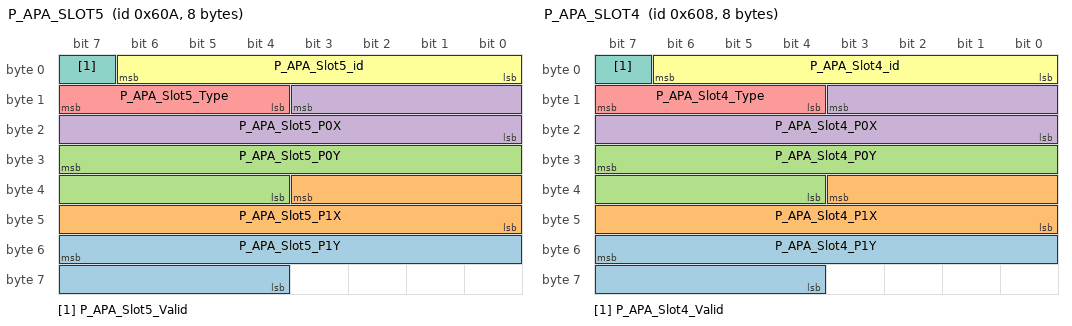
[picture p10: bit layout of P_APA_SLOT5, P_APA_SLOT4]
BO_ 1546 P_APA_SLOT5: 8 TDA4VE
 SG_ P_APA_Slot5_P1Y : 55|12@0+ (0.01,-20.48) [-20.48|20.47] "m"  AutoBox
 SG_ P_APA_Slot5_P1X : 35|12@0+ (0.01,-20.48) [-20.48|20.47] "m"  AutoBox
 SG_ P_APA_Slot5_P0Y : 31|12@0+ (0.01,-20.48) [-20.48|20.47] "m"  AutoBox
 SG_ P_APA_Slot5_P0X : 11|12@0+ (0.01,-20.48) [-20.48|20.47] "m"  AutoBox
 SG_ P_APA_Slot5_Type : 15|4@0+ (1,0) [0|15] ""  AutoBox
 SG_ P_APA_Slot5_id : 6|7@0+ (1,0) [0|127] ""  AutoBox
 SG_ P_APA_Slot5_Valid : 7|1@0+ (1,0) [0|1] ""  AutoBox

BO_ 1545 P_APA_SLOT4_EXT1: 8 TDA4VE
 SG_ P_APA_Slot4_P3Y : 43|12@0+ (0.01,-20.48) [-20.48|20.47] "m"  AutoBox
 SG_ P_APA_Slot4_P3X : 39|12@0+ (0.01,-20.48) [-20.48|20.47] "m"  AutoBox
 SG_ P_APA_Slot4_P2Y : 19|12@0+ (0.01,-20.48) [-20.48|20.47] "m"  AutoBox
 SG_ P_APA_Slot4_P2X : 15|12@0+ (0.01,-20.48) [-20.48|20.47] "m"  AutoBox
 SG_ P_APA_Slot4_Conti1 : 7|1@0+ (1,0) [0|1] ""  AutoBox

BO_ 1544 P_APA_SLOT4: 8 TDA4VE
 SG_ P_APA_Slot4_P1Y : 55|12@0+ (0.01,-20.48) [-20.48|20.47] "m"  AutoBox
 SG_ P_APA_Slot4_P1X : 35|12@0+ (0.01,-20.48) [-20.48|20.47] "m"  AutoBox
 SG_ P_APA_Slot4_P0Y : 31|12@0+ (0.01,-20.48) [-20.48|20.47] "m"  AutoBox
 SG_ P_APA_Slot4_P0X : 11|12@0+ (0.01,-20.48) [-20.48|20.47] "m"  AutoBox
 SG_ P_APA_Slot4_Type : 15|4@0+ (1,0) [0|15] ""  AutoBox
 SG_ P_APA_Slot4_id : 6|7@0+ (1,0) [0|127] ""  AutoBox
 SG_ P_APA_Slot4_Valid : 7|1@0+ (1,0) [0|1] ""  AutoBox

BO_ 1543 P_APA_SLOT3_EXT1: 8 TDA4VE
 SG_ P_APA_Slot3_P3Y : 43|12@0+ (0.01,-20.48) [-20.48|20.47] "m"  AutoBox
 SG_ P_APA_Slot3_P3X : 39|12@0+ (0.01,-20.48) [-20.48|20.47] "m"  AutoBox
 SG_ P_APA_Slot3_P2Y : 19|12@0+ (0.01,-20.48) [-20.48|20.47] "m"  AutoBox
 SG_ P_APA_Slot3_P2X : 15|12@0+ (0.01,-20.48) [-20.48|20.47] "m"  AutoBox
 SG_ P_APA_Slot3_Conti1 : 7|1@0+ (1,0) [0|1] ""  AutoBox

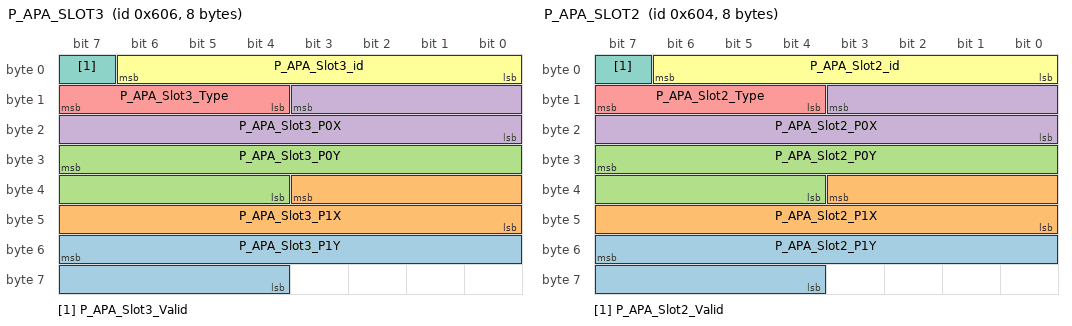
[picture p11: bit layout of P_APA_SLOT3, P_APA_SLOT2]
BO_ 1542 P_APA_SLOT3: 8 TDA4VE
 SG_ P_APA_Slot3_P1Y : 55|12@0+ (0.01,-20.48) [-20.48|20.47] "m"  AutoBox
 SG_ P_APA_Slot3_P1X : 35|12@0+ (0.01,-20.48) [-20.48|20.47] "m"  AutoBox
 SG_ P_APA_Slot3_P0Y : 31|12@0+ (0.01,-20.48) [-20.48|20.47] "m"  AutoBox
 SG_ P_APA_Slot3_P0X : 11|12@0+ (0.01,-20.48) [-20.48|20.47] "m"  AutoBox
 SG_ P_APA_Slot3_Type : 15|4@0+ (1,0) [0|15] ""  AutoBox
 SG_ P_APA_Slot3_id : 6|7@0+ (1,0) [0|127] ""  AutoBox
 SG_ P_APA_Slot3_Valid : 7|1@0+ (1,0) [0|1] ""  AutoBox

BO_ 1541 P_APA_SLOT2_EXT1: 8 TDA4VE
 SG_ P_APA_Slot2_P3Y : 43|12@0+ (0.01,-20.48) [-20.48|20.47] "m"  AutoBox
 SG_ P_APA_Slot2_P3X : 39|12@0+ (0.01,-20.48) [-20.48|20.47] "m"  AutoBox
 SG_ P_APA_Slot2_P2Y : 19|12@0+ (0.01,-20.48) [-20.48|20.47] "m"  AutoBox
 SG_ P_APA_Slot2_P2X : 15|12@0+ (0.01,-20.48) [-20.48|20.47] "m"  AutoBox
 SG_ P_APA_Slot2_Conti1 : 7|1@0+ (1,0) [0|1] ""  AutoBox

BO_ 1540 P_APA_SLOT2: 8 TDA4VE
 SG_ P_APA_Slot2_P1Y : 55|12@0+ (0.01,-20.48) [-20.48|20.47] "m"  AutoBox
 SG_ P_APA_Slot2_P1X : 35|12@0+ (0.01,-20.48) [-20.48|20.47] "m"  AutoBox
 SG_ P_APA_Slot2_P0Y : 31|12@0+ (0.01,-20.48) [-20.48|20.47] "m"  AutoBox
 SG_ P_APA_Slot2_P0X : 11|12@0+ (0.01,-20.48) [-20.48|20.47] "m"  AutoBox
 SG_ P_APA_Slot2_Type : 15|4@0+ (1,0) [0|15] ""  AutoBox
 SG_ P_APA_Slot2_id : 6|7@0+ (1,0) [0|127] ""  AutoBox
 SG_ P_APA_Slot2_Valid : 7|1@0+ (1,0) [0|1] ""  AutoBox

BO_ 1539 P_APA_SLOT1_EXT3: 7 TDA4VE
 SG_ P_APA_Sync_Y : 31|16@0+ (0.01,-327.68) [-327.68|327.67] "m"  AutoBox
 SG_ P_APA_Sync_X : 15|16@0+ (0.01,-327.68) [-327.68|327.67] "m"  AutoBox
 SG_ P_APA_Sync_ANGLE : 47|16@0+ (0.0001,-3.2768) [-3.2768|3.2767] "rad"  AutoBox
 SG_ P_APA_Slot1_Conti3 : 7|1@0+ (1,0) [0|1] ""  AutoBox

BO_ 1538 P_APA_SLOT1_EXT2: 8 TDA4VE
 SG_ P_APA_WheelStopper_P1Y : 43|12@0+ (0.01,-20.48) [-20.48|20.47] "m"  AutoBox
 SG_ P_APA_WheelStopper_P1X : 39|12@0+ (0.01,-20.48) [-20.48|20.47] "m"  AutoBox
 SG_ P_APA_WheelStopper_P0Y : 19|12@0+ (0.01,-20.48) [-20.48|20.47] "m"  AutoBox
 SG_ P_APA_WheelStopper_P0X : 15|12@0+ (0.01,-20.48) [-20.48|20.47] "m"  AutoBox
 SG_ P_APA_Slot1_Conti2 : 7|1@0+ (1,0) [0|1] ""  AutoBox

BO_ 1537 P_APA_SLOT1_EXT1: 8 TDA4VE
 SG_ P_APA_Slot1_P3Y : 43|12@0+ (0.01,-20.48) [-20.48|20.47] "m"  AutoBox
 SG_ P_APA_Slot1_P3X : 39|12@0+ (0.01,-20.48) [-20.48|20.47] "m"  AutoBox
 SG_ P_APA_Slot1_P2Y : 19|12@0+ (0.01,-20.48) [-20.48|20.47] "m"  AutoBox
 SG_ P_APA_Slot1_P2X : 15|12@0+ (0.01,-20.48) [-20.48|20.47] "m"  AutoBox
 SG_ P_APA_Slot1_Conti1 : 7|1@0+ (1,0) [0|1] ""  AutoBox

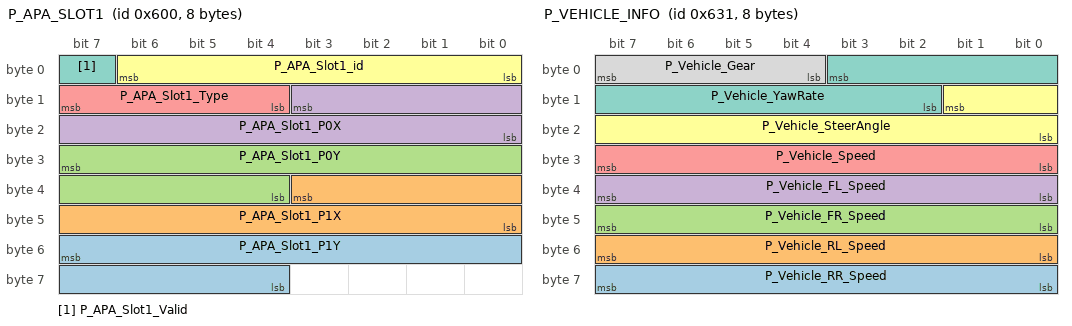
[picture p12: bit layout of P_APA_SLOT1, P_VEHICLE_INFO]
BO_ 1536 P_APA_SLOT1: 8 TDA4VE
 SG_ P_APA_Slot1_P1Y : 55|12@0+ (0.01,-20.48) [-20.48|20.47] "m"  AutoBox
 SG_ P_APA_Slot1_P1X : 35|12@0+ (0.01,-20.48) [-20.48|20.47] "m"  AutoBox
 SG_ P_APA_Slot1_P0Y : 31|12@0+ (0.01,-20.48) [-20.48|20.47] "m"  AutoBox
 SG_ P_APA_Slot1_P0X : 11|12@0+ (0.01,-20.48) [-20.48|20.47] "m"  AutoBox
 SG_ P_APA_Slot1_Type : 15|4@0+ (1,0) [0|15] ""  AutoBox
 SG_ P_APA_Slot1_id : 6|7@0+ (1,0) [0|127] ""  AutoBox
 SG_ P_APA_Slot1_Valid : 7|1@0+ (1,0) [0|1] ""  AutoBox

BO_ 1586 P_SYNC_INFO: 8 AutoBox
 SG_ P_Sync_ANGLE : 47|16@0+ (0.0001,-3.2768) [-3.2768|3.2767] "rad"  TDA4VE
 SG_ P_Sync_Y : 31|16@0+ (0.01,-327.68) [-327.68|327.67] "m"  TDA4VE
 SG_ P_Sync_X : 15|16@0+ (0.01,-327.68) [-327.68|327.67] "m"  TDA4VE
 SG_ P_Sync_Valid : 7|1@0+ (1,0) [0|1] ""  TDA4VE

BO_ 1585 P_VEHICLE_INFO: 8 AutoBox
 SG_ P_Vehicle_RR_Speed : 63|8@0+ (0.05,0) [0|12.7] "m/s"  TDA4VE
 SG_ P_Vehicle_RL_Speed : 55|8@0+ (0.05,0) [0|12.7] "m/s"  TDA4VE
 SG_ P_Vehicle_FR_Speed : 47|8@0+ (0.05,0) [0|12.7] "m/s"  TDA4VE
 SG_ P_Vehicle_FL_Speed : 39|8@0+ (0.05,0) [0|12.7] "m/s"  TDA4VE
 SG_ P_Vehicle_Speed : 31|8@0+ (0.05,0) [0|12.7] "m/s"  TDA4VE
 SG_ P_Vehicle_SteerAngle : 9|10@0+ (4,-2048) [-2048|2044] "deg"  TDA4VE
 SG_ P_Vehicle_YawRate : 3|10@0+ (0.2,-102.4) [-102.4|102.2] "deg/s"  TDA4VE
 SG_ P_Vehicle_Gear : 7|4@0+ (1,0) [0|15] ""  TDA4VE

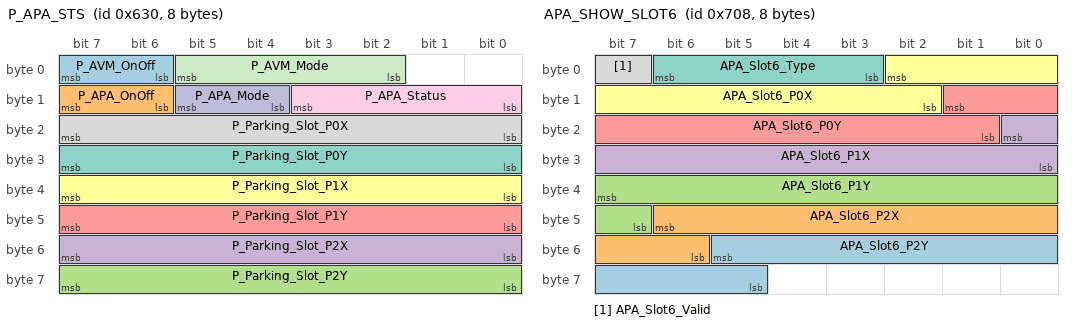
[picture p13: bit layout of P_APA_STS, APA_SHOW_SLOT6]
BO_ 1584 P_APA_STS: 8 AutoBox
 SG_ P_AVM_OnOff : 7|2@0+ (1,0) [0|3] "" Vector__XXX
 SG_ P_APA_OnOff : 15|2@0+ (1,0) [0|3] "" Vector__XXX
 SG_ P_Parking_Slot_P2Y : 63|8@0+ (0.1,-12.8) [-12.8|12.7] "m"  TDA4VE
 SG_ P_Parking_Slot_P2X : 55|8@0+ (0.1,-12.8) [-12.8|12.7] "m"  TDA4VE
 SG_ P_Parking_Slot_P1Y : 47|8@0+ (0.1,-12.8) [-12.8|12.7] "m"  TDA4VE
 SG_ P_Parking_Slot_P1X : 39|8@0+ (0.1,-12.8) [-12.8|12.7] "m"  TDA4VE
 SG_ P_Parking_Slot_P0Y : 31|8@0+ (0.1,-12.8) [-12.8|12.7] "m"  TDA4VE
 SG_ P_Parking_Slot_P0X : 23|8@0+ (0.1,-12.8) [-12.8|12.7] "m"  TDA4VE
 SG_ P_APA_Status : 11|4@0+ (1,0) [0|15] ""  TDA4VE
 SG_ P_APA_Mode : 13|2@0+ (1,0) [0|3] ""  TDA4VE
 SG_ P_AVM_Mode : 5|4@0+ (1,0) [0|15] ""  TDA4VE

BO_ 1800 APA_SHOW_SLOT6: 8 AutoBox
 SG_ APA_Slot6_P2Y : 53|9@0+ (0.1,-25.6) [-25.6|25.5] "m"  HMI_Simulation
 SG_ APA_Slot6_P2X : 46|9@0+ (0.1,-25.6) [-25.6|25.5] "m"  HMI_Simulation
 SG_ APA_Slot6_P1Y : 39|9@0+ (0.1,-25.6) [-25.6|25.5] "m"  HMI_Simulation
 SG_ APA_Slot6_P1X : 16|9@0+ (0.1,-25.6) [-25.6|25.5] "m"  HMI_Simulation
 SG_ APA_Slot6_P0Y : 9|9@0+ (0.1,-25.6) [-25.6|25.5] "m"  HMI_Simulation
 SG_ APA_Slot6_P0X : 2|9@0+ (0.1,-25.6) [-25.6|25.5] "m"  HMI_Simulation
 SG_ APA_Slot6_Type : 6|4@0+ (1,0) [0|15] ""  HMI_Simulation
 SG_ APA_Slot6_Valid : 7|1@0+ (1,0) [0|1] ""  HMI_Simulation

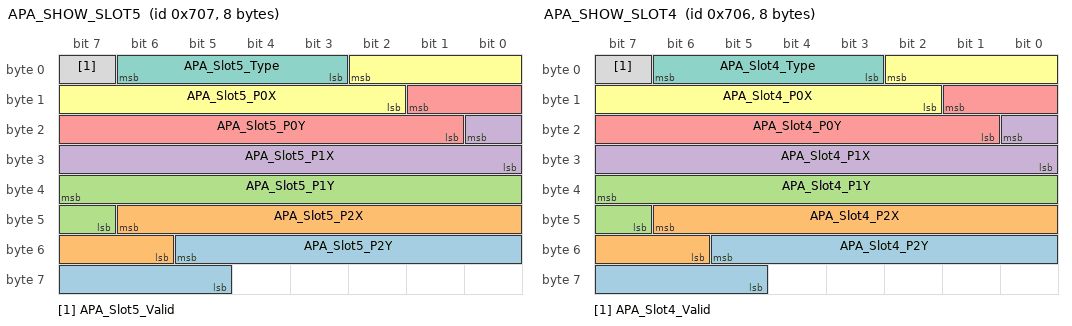
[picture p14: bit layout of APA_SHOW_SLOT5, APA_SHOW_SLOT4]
BO_ 1799 APA_SHOW_SLOT5: 8 AutoBox
 SG_ APA_Slot5_P2Y : 53|9@0+ (0.1,-25.6) [-25.6|25.5] "m"  HMI_Simulation
 SG_ APA_Slot5_P2X : 46|9@0+ (0.1,-25.6) [-25.6|25.5] "m"  HMI_Simulation
 SG_ APA_Slot5_P1Y : 39|9@0+ (0.1,-25.6) [-25.6|25.5] "m"  HMI_Simulation
 SG_ APA_Slot5_P1X : 16|9@0+ (0.1,-25.6) [-25.6|25.5] "m"  HMI_Simulation
 SG_ APA_Slot5_P0Y : 9|9@0+ (0.1,-25.6) [-25.6|25.5] "m"  HMI_Simulation
 SG_ APA_Slot5_P0X : 2|9@0+ (0.1,-25.6) [-25.6|25.5] "m"  HMI_Simulation
 SG_ APA_Slot5_Type : 6|4@0+ (1,0) [0|15] ""  HMI_Simulation
 SG_ APA_Slot5_Valid : 7|1@0+ (1,0) [0|1] ""  HMI_Simulation

BO_ 1798 APA_SHOW_SLOT4: 8 AutoBox
 SG_ APA_Slot4_P2Y : 53|9@0+ (0.1,-25.6) [-25.6|25.5] "m"  HMI_Simulation
 SG_ APA_Slot4_P2X : 46|9@0+ (0.1,-25.6) [-25.6|25.5] "m"  HMI_Simulation
 SG_ APA_Slot4_P1Y : 39|9@0+ (0.1,-25.6) [-25.6|25.5] "m"  HMI_Simulation
 SG_ APA_Slot4_P1X : 16|9@0+ (0.1,-25.6) [-25.6|25.5] "m"  HMI_Simulation
 SG_ APA_Slot4_P0Y : 9|9@0+ (0.1,-25.6) [-25.6|25.5] "m"  HMI_Simulation
 SG_ APA_Slot4_P0X : 2|9@0+ (0.1,-25.6) [-25.6|25.5] "m"  HMI_Simulation
 SG_ APA_Slot4_Type : 6|4@0+ (1,0) [0|15] ""  HMI_Simulation
 SG_ APA_Slot4_Valid : 7|1@0+ (1,0) [0|1] ""  HMI_Simulation

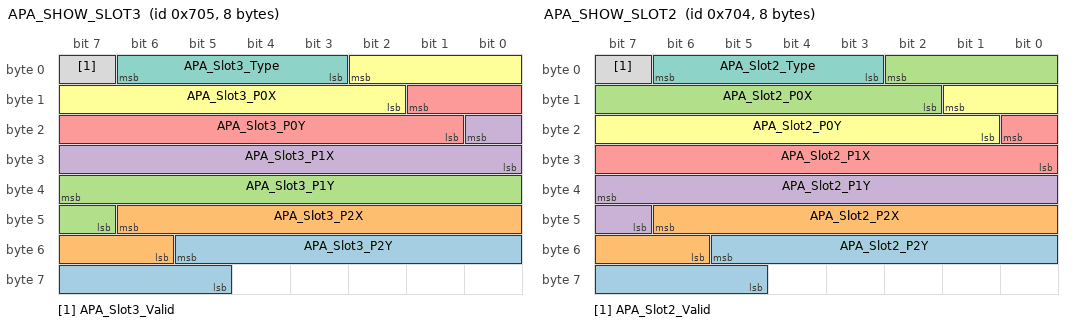
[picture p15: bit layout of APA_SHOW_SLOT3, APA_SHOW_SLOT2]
BO_ 1797 APA_SHOW_SLOT3: 8 AutoBox
 SG_ APA_Slot3_P2Y : 53|9@0+ (0.1,-25.6) [-25.6|25.5] "m"  HMI_Simulation
 SG_ APA_Slot3_P2X : 46|9@0+ (0.1,-25.6) [-25.6|25.5] "m"  HMI_Simulation
 SG_ APA_Slot3_P1Y : 39|9@0+ (0.1,-25.6) [-25.6|25.5] "m"  HMI_Simulation
 SG_ APA_Slot3_P1X : 16|9@0+ (0.1,-25.6) [-25.6|25.5] "m"  HMI_Simulation
 SG_ APA_Slot3_P0Y : 9|9@0+ (0.1,-25.6) [-25.6|25.5] "m"  HMI_Simulation
 SG_ APA_Slot3_P0X : 2|9@0+ (0.1,-25.6) [-25.6|25.5] "m"  HMI_Simulation
 SG_ APA_Slot3_Type : 6|4@0+ (1,0) [0|15] ""  HMI_Simulation
 SG_ APA_Slot3_Valid : 7|1@0+ (1,0) [0|1] ""  HMI_Simulation

BO_ 1796 APA_SHOW_SLOT2: 8 AutoBox
 SG_ APA_Slot2_P2Y : 53|9@0+ (0.1,-25.6) [-25.6|25.5] "m"  HMI_Simulation
 SG_ APA_Slot2_P2X : 46|9@0+ (0.1,-25.6) [-25.6|25.5] "m"  HMI_Simulation
 SG_ APA_Slot2_P0X : 2|9@0+ (0.1,-25.6) [-25.6|25.5] "m"  HMI_Simulation
 SG_ APA_Slot2_P1Y : 39|9@0+ (0.1,-25.6) [-25.6|25.5] "m"  HMI_Simulation
 SG_ APA_Slot2_P1X : 16|9@0+ (0.1,-25.6) [-25.6|25.5] "m"  HMI_Simulation
 SG_ APA_Slot2_P0Y : 9|9@0+ (0.1,-25.6) [-25.6|25.5] "m"  HMI_Simulation
 SG_ APA_Slot2_Type : 6|4@0+ (1,0) [0|15] ""  HMI_Simulation
 SG_ APA_Slot2_Valid : 7|1@0+ (1,0) [0|1] ""  HMI_Simulation

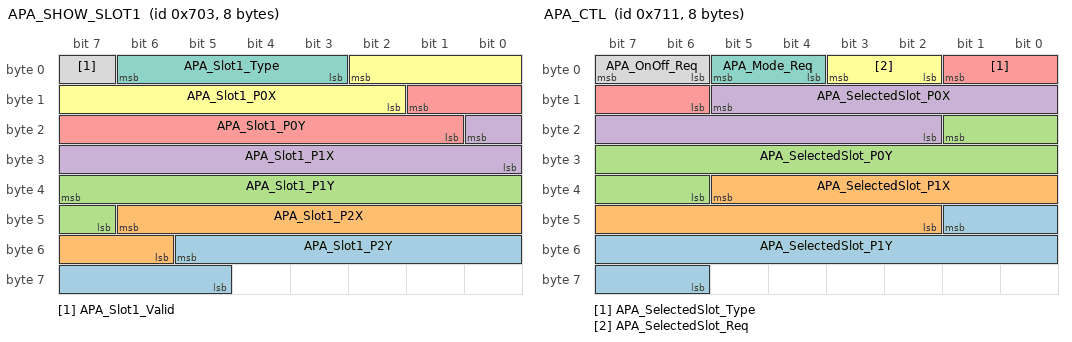
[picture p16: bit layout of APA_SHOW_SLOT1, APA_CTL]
BO_ 1795 APA_SHOW_SLOT1: 8 AutoBox
 SG_ APA_Slot1_P2Y : 53|9@0+ (0.1,-25.6) [-25.6|25.5] "m"  HMI_Simulation
 SG_ APA_Slot1_P2X : 46|9@0+ (0.1,-25.6) [-25.6|25.5] "m"  HMI_Simulation
 SG_ APA_Slot1_P1Y : 39|9@0+ (0.1,-25.6) [-25.6|25.5] "m"  HMI_Simulation
 SG_ APA_Slot1_P1X : 16|9@0+ (0.1,-25.6) [-25.6|25.5] "m"  HMI_Simulation
 SG_ APA_Slot1_P0Y : 9|9@0+ (0.1,-25.6) [-25.6|25.5] "m"  HMI_Simulation
 SG_ APA_Slot1_P0X : 2|9@0+ (0.1,-25.6) [-25.6|25.5] "m"  HMI_Simulation
 SG_ APA_Slot1_Type : 6|4@0+ (1,0) [0|15] ""  HMI_Simulation
 SG_ APA_Slot1_Valid : 7|1@0+ (1,0) [0|1] ""  HMI_Simulation

BO_ 1809 APA_CTL: 8 HMI_Simulation
 SG_ APA_SelectedSlot_P1Y : 41|12@0+ (0.01,-20.48) [-20.48|20.47] "m"  AutoBox
 SG_ APA_SelectedSlot_P1X : 37|12@0+ (0.01,-20.48) [-20.48|20.47] "m"  AutoBox
 SG_ APA_SelectedSlot_P0Y : 17|12@0+ (0.01,-20.48) [-20.48|20.47] "m"  AutoBox
 SG_ APA_SelectedSlot_P0X : 13|12@0+ (0.01,-20.48) [-20.48|20.47] "m"  AutoBox
 SG_ APA_SelectedSlot_Type : 1|4@0+ (1,0) [0|15] ""  AutoBox
 SG_ APA_SelectedSlot_Req : 3|2@0+ (1,0) [0|3] ""  AutoBox
 SG_ APA_Mode_Req : 5|2@0+ (1,0) [0|3] ""  AutoBox
 SG_ APA_OnOff_Req : 7|2@0+ (1,0) [0|3] ""  AutoBox

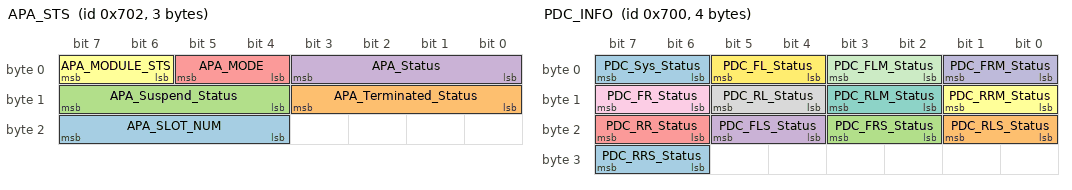
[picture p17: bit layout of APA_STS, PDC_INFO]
BO_ 1794 APA_STS: 3 AutoBox
 SG_ APA_SLOT_NUM : 23|4@0+ (1,0) [0|15] ""  HMI_Simulation
 SG_ APA_Terminated_Status : 11|4@0+ (1,0) [0|15] ""  HMI_Simulation
 SG_ APA_Suspend_Status : 15|4@0+ (1,0) [0|15] ""  HMI_Simulation
 SG_ APA_Status : 3|4@0+ (1,0) [0|15] ""  HMI_Simulation
 SG_ APA_MODE : 5|2@0+ (1,0) [0|3] ""  HMI_Simulation
 SG_ APA_MODULE_STS : 7|2@0+ (1,0) [0|3] ""  HMI_Simulation

BO_ 1808 AVM_CTL: 1 HMI_Simulation
 SG_ AVM_Mode_Req : 5|4@0+ (1,0) [0|15] ""  TDA4VE
 SG_ AVM_OnOff_Req : 7|2@0+ (1,0) [0|3] ""  TDA4VE

BO_ 1792 PDC_INFO: 4 AutoBox
 SG_ PDC_RRS_Status : 31|2@0+ (1,0) [0|3] ""  HMI_Simulation
 SG_ PDC_RLS_Status : 17|2@0+ (1,0) [0|3] ""  HMI_Simulation
 SG_ PDC_FRS_Status : 19|2@0+ (1,0) [0|3] ""  HMI_Simulation
 SG_ PDC_FLS_Status : 21|2@0+ (1,0) [0|3] ""  HMI_Simulation
 SG_ PDC_RR_Status : 23|2@0+ (1,0) [0|3] ""  HMI_Simulation
 SG_ PDC_RRM_Status : 9|2@0+ (1,0) [0|3] ""  HMI_Simulation
 SG_ PDC_RLM_Status : 11|2@0+ (1,0) [0|3] ""  HMI_Simulation
 SG_ PDC_RL_Status : 13|2@0+ (1,0) [0|3] ""  HMI_Simulation
 SG_ PDC_FR_Status : 15|2@0+ (1,0) [0|3] ""  HMI_Simulation
 SG_ PDC_FRM_Status : 1|2@0+ (1,0) [0|3] ""  HMI_Simulation
 SG_ PDC_FLM_Status : 3|2@0+ (1,0) [0|3] ""  HMI_Simulation
 SG_ PDC_FL_Status : 5|2@0+ (1,0) [0|3] ""  HMI_Simulation
 SG_ PDC_Sys_Status : 7|2@0+ (1,0) [0|3] ""  HMI_Simulation

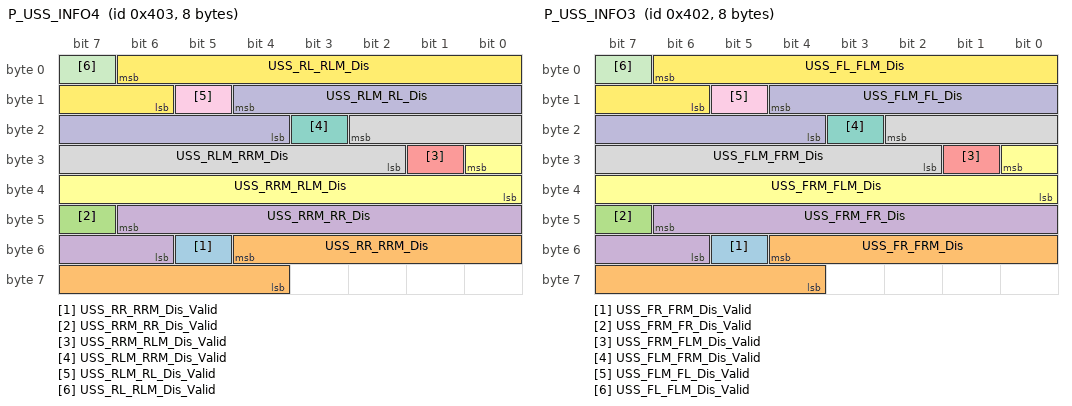
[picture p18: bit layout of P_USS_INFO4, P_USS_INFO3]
BO_ 1027 P_USS_INFO4: 8 TeampoEVB
 SG_ USS_RR_RRM_Dis_Valid : 53|1@0+ (1,0) [0|1] ""  AutoBox
 SG_ USS_RR_RRM_Dis : 52|9@0+ (0.02,0) [0|10.22] "m"  AutoBox
 SG_ USS_RRM_RR_Dis_Valid : 47|1@0+ (1,0) [0|1] ""  AutoBox
 SG_ USS_RRM_RR_Dis : 46|9@0+ (0.02,0) [0|10.22] "m"  AutoBox
 SG_ USS_RRM_RLM_Dis_Valid : 25|1@0+ (1,0) [0|1] ""  AutoBox
 SG_ USS_RRM_RLM_Dis : 24|9@0+ (0.02,0) [0|10.22] "m"  AutoBox
 SG_ USS_RLM_RRM_Dis_Valid : 19|1@0+ (1,0) [0|1] ""  AutoBox
 SG_ USS_RLM_RRM_Dis : 18|9@0+ (0.02,0) [0|10.22] "m"  AutoBox
 SG_ USS_RLM_RL_Dis_Valid : 13|1@0+ (1,0) [0|1] ""  AutoBox
 SG_ USS_RLM_RL_Dis : 12|9@0+ (0.02,0) [0|10.22] "m"  AutoBox
 SG_ USS_RL_RLM_Dis_Valid : 7|1@0+ (1,0) [0|1] ""  AutoBox
 SG_ USS_RL_RLM_Dis : 6|9@0+ (0.02,0) [0|10.22] "m"  AutoBox

BO_ 1026 P_USS_INFO3: 8 TeampoEVB
 SG_ USS_FR_FRM_Dis_Valid : 53|1@0+ (1,0) [0|1] ""  AutoBox
 SG_ USS_FR_FRM_Dis : 52|9@0+ (0.02,0) [0|10.22] "m"  AutoBox
 SG_ USS_FRM_FR_Dis_Valid : 47|1@0+ (1,0) [0|1] ""  AutoBox
 SG_ USS_FRM_FR_Dis : 46|9@0+ (0.02,0) [0|10.22] "m"  AutoBox
 SG_ USS_FRM_FLM_Dis_Valid : 25|1@0+ (1,0) [0|1] ""  AutoBox
 SG_ USS_FRM_FLM_Dis : 24|9@0+ (0.02,0) [0|10.22] "m"  AutoBox
 SG_ USS_FLM_FRM_Dis_Valid : 19|1@0+ (1,0) [0|1] ""  AutoBox
 SG_ USS_FLM_FRM_Dis : 18|9@0+ (0.02,0) [0|10.22] "m"  AutoBox
 SG_ USS_FLM_FL_Dis_Valid : 13|1@0+ (1,0) [0|1] ""  AutoBox
 SG_ USS_FLM_FL_Dis : 12|9@0+ (0.02,0) [0|10.22] "m"  AutoBox
 SG_ USS_FL_FLM_Dis_Valid : 7|1@0+ (1,0) [0|1] ""  AutoBox
 SG_ USS_FL_FLM_Dis : 6|9@0+ (0.02,0) [0|10.22] "m"  AutoBox

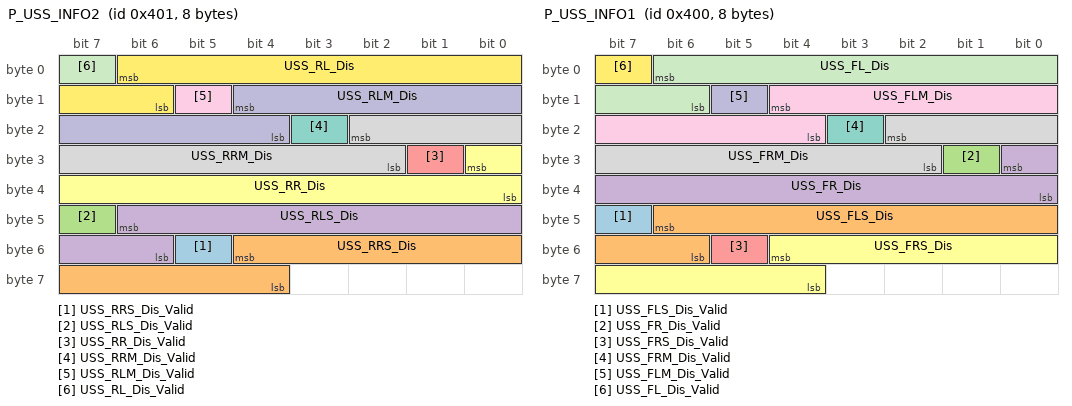
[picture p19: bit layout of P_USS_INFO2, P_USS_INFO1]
BO_ 1025 P_USS_INFO2: 8 TeampoEVB
 SG_ USS_RRS_Dis_Valid : 53|1@0+ (1,0) [0|1] ""  AutoBox
 SG_ USS_RRS_Dis : 52|9@0+ (0.02,0) [0|10.22] "m"  AutoBox
 SG_ USS_RLS_Dis_Valid : 47|1@0+ (1,0) [0|1] ""  AutoBox
 SG_ USS_RLS_Dis : 46|9@0+ (0.02,0) [0|10.22] "m"  AutoBox
 SG_ USS_RR_Dis_Valid : 25|1@0+ (1,0) [0|1] ""  AutoBox
 SG_ USS_RR_Dis : 24|9@0+ (0.02,0) [0|10.22] "m"  AutoBox
 SG_ USS_RRM_Dis_Valid : 19|1@0+ (1,0) [0|1] ""  AutoBox
 SG_ USS_RRM_Dis : 18|9@0+ (0.02,0) [0|10.22] "m"  AutoBox
 SG_ USS_RLM_Dis_Valid : 13|1@0+ (1,0) [0|1] ""  AutoBox
 SG_ USS_RLM_Dis : 12|9@0+ (0.02,0) [0|10.22] "m"  AutoBox
 SG_ USS_RL_Dis_Valid : 7|1@0+ (1,0) [0|1] ""  AutoBox
 SG_ USS_RL_Dis : 6|9@0+ (0.02,0) [0|10.22] "m"  AutoBox

BO_ 1024 P_USS_INFO1: 8 TeampoEVB
 SG_ USS_FLS_Dis_Valid : 47|1@0+ (1,0) [0|1] ""  AutoBox
 SG_ USS_FLS_Dis : 46|9@0+ (0.02,0) [0|10.22] "m"  AutoBox
 SG_ USS_FR_Dis_Valid : 25|1@0+ (1,0) [0|1] ""  AutoBox
 SG_ USS_FR_Dis : 24|9@0+ (0.02,0) [0|10.22] "m"  AutoBox
 SG_ USS_FRS_Dis_Valid : 53|1@0+ (1,0) [0|1] ""  AutoBox
 SG_ USS_FRS_Dis : 52|9@0+ (0.02,0) [0|10.22] "m"  AutoBox
 SG_ USS_FRM_Dis_Valid : 19|1@0+ (1,0) [0|1] ""  AutoBox
 SG_ USS_FRM_Dis : 18|9@0+ (0.02,0) [0|10.22] "m"  AutoBox
 SG_ USS_FLM_Dis : 12|9@0+ (0.02,0) [0|10.22] "m"  AutoBox
 SG_ USS_FLM_Dis_Valid : 13|1@0+ (1,0) [0|1] ""  AutoBox
 SG_ USS_FL_Dis : 6|9@0+ (0.02,0) [0|10.22] "m"  AutoBox
 SG_ USS_FL_Dis_Valid : 7|1@0+ (1,0) [0|1] ""  AutoBox

CM_ BO_ 3221225472 "This is a message for not used signals, created by Vector CANdb++ DBC OLE DB Provider.";
CM_ BO_ 776 "0x710-->1808. From HMI_Simulation to AutoBox .";
CM_ BO_ 775 "0x710-->1808. From HMI_Simulation to AutoBox .";
CM_ BO_ 774 "0x710-->1808. From HMI_Simulation to AutoBox .";
CM_ BO_ 773 "0x710-->1808. From HMI_Simulation to AutoBox .";
CM_ BO_ 772 "0x710-->1808. From HMI_Simulation to AutoBox .";
CM_ BO_ 771 "0x710-->1808. From HMI_Simulation to AutoBox .";
CM_ BO_ 770 "0x710-->1808. From HMI_Simulation to AutoBox .";
CM_ BO_ 769 "0x710-->1808. From HMI_Simulation to AutoBox .";
CM_ BO_ 1360 "0x403-->1027. From TeampoEVB to AutoBox .";
CM_ BO_ 1359 "0x403-->1027. From TeampoEVB to AutoBox .";
CM_ BO_ 1358 "0x403-->1027. From TeampoEVB to AutoBox .";
CM_ BO_ 1357 "0x403-->1027. From TeampoEVB to AutoBox .";
CM_ BO_ 1356 "0x403-->1027. From TeampoEVB to AutoBox .";
CM_ BO_ 1355 "0x403-->1027. From TeampoEVB to AutoBox .";
CM_ BO_ 1354 "0x403-->1027. From TeampoEVB to AutoBox .";
CM_ BO_ 1353 "0x403-->1027. From TeampoEVB to AutoBox .";
CM_ BO_ 1352 "0x403-->1027. From TeampoEVB to AutoBox .";
CM_ BO_ 1351 "0x403-->1027. From TeampoEVB to AutoBox .";
CM_ BO_ 1350 "0x403-->1027. From TeampoEVB to AutoBox .";
CM_ BO_ 1349 "0x403-->1027. From TeampoEVB to AutoBox .";
CM_ BO_ 1348 "0x403-->1027. From TeampoEVB to AutoBox .";
CM_ BO_ 1347 "0x403-->1027. From TeampoEVB to AutoBox .";
CM_ BO_ 1346 "0x403-->1027. From TeampoEVB to AutoBox .";
CM_ BO_ 1345 "0x403-->1027. From TeampoEVB to AutoBox .";
CM_ BO_ 1344 "0x403-->1027. From TeampoEVB to AutoBox .";
CM_ BO_ 1343 "0x403-->1027. From TeampoEVB to AutoBox .";
CM_ BO_ 1342 "0x403-->1027. From TeampoEVB to AutoBox .";
CM_ BO_ 1341 "0x403-->1027. From TeampoEVB to AutoBox .";
CM_ BO_ 1340 "0x403-->1027. From TeampoEVB to AutoBox .";
CM_ BO_ 1339 "0x403-->1027. From TeampoEVB to AutoBox .";
CM_ BO_ 1338 "0x403-->1027. From TeampoEVB to AutoBox .";
CM_ BO_ 1337 "0x403-->1027. From TeampoEVB to AutoBox .";
CM_ BO_ 1336 "0x403-->1027. From TeampoEVB to AutoBox .";
CM_ BO_ 1335 "0x403-->1027. From TeampoEVB to AutoBox .";
CM_ BO_ 1334 "0x403-->1027. From TeampoEVB to AutoBox .";
CM_ BO_ 1333 "0x403-->1027. From TeampoEVB to AutoBox .";
CM_ BO_ 1332 "0x403-->1027. From TeampoEVB to AutoBox .";
CM_ BO_ 1331 "0x403-->1027. From TeampoEVB to AutoBox .";
CM_ BO_ 1330 "0x403-->1027. From TeampoEVB to AutoBox .";
CM_ BO_ 1329 "0x403-->1027. From TeampoEVB to AutoBox .";
CM_ BO_ 1328 "0x403-->1027. From TeampoEVB to AutoBox .";
CM_ BO_ 1327 "0x403-->1027. From TeampoEVB to AutoBox .";
CM_ BO_ 1326 "0x403-->1027. From TeampoEVB to AutoBox .";
CM_ BO_ 1325 "0x403-->1027. From TeampoEVB to AutoBox .";
CM_ BO_ 1324 "0x403-->1027. From TeampoEVB to AutoBox .";
CM_ BO_ 1323 "0x403-->1027. From TeampoEVB to AutoBox .";
CM_ BO_ 1322 "0x403-->1027. From TeampoEVB to AutoBox .";
CM_ BO_ 1321 "0x403-->1027. From TeampoEVB to AutoBox .";
CM_ BO_ 1313 "0x403-->1027. From TeampoEVB to AutoBox .";
CM_ BO_ 1320 "0x403-->1027. From TeampoEVB to AutoBox .";
CM_ BO_ 1319 "0x403-->1027. From TeampoEVB to AutoBox .";
CM_ BO_ 1318 "0x403-->1027. From TeampoEVB to AutoBox .";
CM_ BO_ 1317 "0x403-->1027. From TeampoEVB to AutoBox .";
CM_ BO_ 1316 "0x403-->1027. From TeampoEVB to AutoBox .";
CM_ BO_ 1315 "0x403-->1027. From TeampoEVB to AutoBox .";
CM_ BO_ 1314 "0x403-->1027. From TeampoEVB to AutoBox .";
CM_ BO_ 1312 "0x403-->1027. From TeampoEVB to AutoBox .";
CM_ BO_ 1311 "0x403-->1027. From TeampoEVB to AutoBox .";
CM_ BO_ 1310 "0x403-->1027. From TeampoEVB to AutoBox .";
CM_ BO_ 1309 "0x403-->1027. From TeampoEVB to AutoBox .";
CM_ BO_ 1308 "0x403-->1027. From TeampoEVB to AutoBox .";
CM_ BO_ 1307 "0x403-->1027. From TeampoEVB to AutoBox .";
CM_ BO_ 1306 "0x403-->1027. From TeampoEVB to AutoBox .";
CM_ BO_ 1305 "0x403-->1027. From TeampoEVB to AutoBox .";
CM_ BO_ 1304 "0x403-->1027. From TeampoEVB to AutoBox .";
CM_ BO_ 1303 "0x403-->1027. From TeampoEVB to AutoBox .";
CM_ BO_ 1302 "0x403-->1027. From TeampoEVB to AutoBox .";
CM_ BO_ 1301 "0x403-->1027. From TeampoEVB to AutoBox .";
CM_ BO_ 1300 "0x403-->1027. From TeampoEVB to AutoBox .";
CM_ BO_ 1299 "0x403-->1027. From TeampoEVB to AutoBox .";
CM_ BO_ 1298 "0x403-->1027. From TeampoEVB to AutoBox .";
CM_ BO_ 1297 "0x403-->1027. From TeampoEVB to AutoBox .";
CM_ BO_ 1296 "0x403-->1027. From TeampoEVB to AutoBox .";
CM_ BO_ 1295 "0x403-->1027. From TeampoEVB to AutoBox .";
CM_ BO_ 1294 "0x403-->1027. From TeampoEVB to AutoBox .";
CM_ BO_ 1293 "0x403-->1027. From TeampoEVB to AutoBox .";
CM_ BO_ 1292 "0x403-->1027. From TeampoEVB to AutoBox .";
CM_ BO_ 1291 "0x403-->1027. From TeampoEVB to AutoBox .";
CM_ BO_ 1290 "0x403-->1027. From TeampoEVB to AutoBox .";
CM_ BO_ 1289 "0x403-->1027. From TeampoEVB to AutoBox .";
CM_ BO_ 1288 "0x403-->1027. From TeampoEVB to AutoBox .";
CM_ BO_ 1287 "0x403-->1027. From TeampoEVB to AutoBox .";
CM_ BO_ 1286 "0x403-->1027. From TeampoEVB to AutoBox .";
CM_ BO_ 1284 "0x403-->1027. From TeampoEVB to AutoBox .";
CM_ BO_ 1285 "0x403-->1027. From TeampoEVB to AutoBox .";
CM_ BO_ 1283 "0x403-->1027. From TeampoEVB to AutoBox .";
CM_ BO_ 1282 "0x403-->1027. From TeampoEVB to AutoBox .";
CM_ BO_ 1281 "0x403-->1027. From TeampoEVB to AutoBox .";
CM_ BO_ 1827 "0x723-->1827. From TDA4VE to AFC.";
CM_ BO_ 1826 "0x722-->1826. From TDA4VE to AFC.";
CM_ BO_ 1825 "0x721-->1825. From TDA4VE to AFC.";
CM_ BO_ 1824 "0x720-->1824. From TDA4VE to AFC.";
CM_ BO_ 1556 "0x614-->1556. From TDA4VE to AutoBox.";
CM_ BO_ 1555 "0x613-->1555. From TDA4VE to AutoBox.";
CM_ BO_ 1554 "0x612-->1554. From TDA4VE to AutoBox.";
CM_ BO_ 1553 "0x611-->1553. From TDA4VE to AutoBox.";
CM_ BO_ 1552 "0x610-->1552. From TDA4VE to AutoBox.";
CM_ BO_ 1580 "0x62C-->1580. From TDA4VE to AutoBox.";
CM_ BO_ 1579 "0x62B-->1579. From TDA4VE to AutoBox.";
CM_ BO_ 1578 "0x62A-->1578. From TDA4VE to AutoBox.";
CM_ BO_ 1577 "0x629-->1577. From TDA4VE to AutoBox.";
CM_ BO_ 1576 "0x628-->1576. From TDA4VE to AutoBox.";
CM_ BO_ 1575 "0x627-->1575. From TDA4VE to AutoBox.";
CM_ BO_ 1574 "0x626-->1574. From TDA4VE to AutoBox.";
CM_ BO_ 1573 "0x625-->1573. From TDA4VE to AutoBox.";
CM_ BO_ 1572 "0x624-->1572. From TDA4VE to AutoBox.";
CM_ BO_ 1571 "0x623-->1571. From TDA4VE to AutoBox.";
CM_ BO_ 1570 "0x622-->1570. From TDA4VE to AutoBox.";
CM_ BO_ 1569 "0x621-->1569. From TDA4VE to AutoBox.";
CM_ BO_ 1568 "0x620-->1568. From TDA4VE to AutoBox.";
CM_ BO_ 1549 "0x60D-->1549. From TDA4VE to AutoBox.";
CM_ BO_ 1548 "0x60C-->1548. From TDA4VE to AutoBox.";
CM_ BO_ 1547 "0x60B-->1547. From TDA4VE to AutoBox.";
CM_ BO_ 1546 "0x60A-->1546. From TDA4VE to AutoBox.";
CM_ BO_ 1545 "0x609-->1545. From TDA4VE to AutoBox.";
CM_ BO_ 1544 "0x608-->1544. From TDA4VE to AutoBox.";
CM_ BO_ 1543 "0x607-->1543. From TDA4VE to AutoBox.";
CM_ BO_ 1542 "0x606-->1542. From TDA4VE to AutoBox.";
CM_ BO_ 1541 "0x605-->1541. From TDA4VE to AutoBox.";
CM_ BO_ 1540 "0x604-->1540. From TDA4VE to AutoBox.";
CM_ BO_ 1539 "0x603-->1539. From TDA4VE to AutoBox.";
CM_ BO_ 1538 "0x602-->1538. From TDA4VE to AutoBox.";
CM_ BO_ 1537 "0x601-->1537. From TDA4VE to AutoBox.";
CM_ BO_ 1536 "0x600-->1536. From TDA4VE to AutoBox.";
CM_ BO_ 1586 "0x632-->1586. From AutoBox to TDA4VE .";
CM_ BO_ 1585 "0x631-->1585. From AutoBox to TDA4VE .";
CM_ BO_ 1584 "0x630-->1584. From AutoBox to TDA4VE .";
CM_ BO_ 1800 "0x708-->1800. From AutoBox to HMI_Simulation.";
CM_ BO_ 1799 "0x707-->1799. From AutoBox to HMI_Simulation.";
CM_ BO_ 1798 "0x706-->1798. From AutoBox to HMI_Simulation.";
CM_ BO_ 1797 "0x705-->1797. From AutoBox to HMI_Simulation.";
CM_ BO_ 1796 "0x704-->1796. From AutoBox to HMI_Simulation.";
CM_ BO_ 1795 "0x703-->1795. From AutoBox to HMI_Simulation.";
CM_ BO_ 1809 "0x711-->1809. From HMI_Simulation to AutoBox .";
CM_ BO_ 1794 "0x702-->1794. From AutoBox to HMI_Simulation .";
CM_ BO_ 1808 "0x710-->1808. From HMI_Simulation to AutoBox .";
CM_ BO_ 1792 "0x700-->1792. From AutoBox to HMI_Simulation.";
CM_ BO_ 1027 "0x403-->1027. From TeampoEVB to AutoBox .";
CM_ BO_ 1026 "0x402-->1026. From TeampoEVB to AutoBox .";
CM_ BO_ 1025 "0x401-->1025. From TeampoEVB to AutoBox .";
CM_ BO_ 1024 "0x400-->1024. From TeampoEVB to AutoBox .";
BA_DEF_ BO_  "GenMsgSendType" ENUM  "Cyclic","Event";
BA_DEF_ BO_  "GenMsgCycleTime" INT 0 65535;
BA_DEF_DEF_  "GenMsgSendType" "Cyclic";
BA_DEF_DEF_  "GenMsgCycleTime" 0;
BA_ "GenMsgCycleTime" BO_ 776 50;
BA_ "GenMsgCycleTime" BO_ 775 50;
BA_ "GenMsgCycleTime" BO_ 774 50;
BA_ "GenMsgCycleTime" BO_ 773 50;
BA_ "GenMsgCycleTime" BO_ 772 50;
BA_ "GenMsgCycleTime" BO_ 771 50;
BA_ "GenMsgCycleTime" BO_ 770 50;
BA_ "GenMsgCycleTime" BO_ 769 50;
BA_ "GenMsgCycleTime" BO_ 1360 50;
BA_ "GenMsgCycleTime" BO_ 1359 50;
BA_ "GenMsgCycleTime" BO_ 1358 50;
BA_ "GenMsgCycleTime" BO_ 1357 50;
BA_ "GenMsgCycleTime" BO_ 1356 50;
BA_ "GenMsgCycleTime" BO_ 1355 50;
BA_ "GenMsgCycleTime" BO_ 1354 50;
BA_ "GenMsgCycleTime" BO_ 1353 50;
BA_ "GenMsgCycleTime" BO_ 1352 50;
BA_ "GenMsgCycleTime" BO_ 1351 50;
BA_ "GenMsgCycleTime" BO_ 1350 50;
BA_ "GenMsgCycleTime" BO_ 1349 50;
BA_ "GenMsgCycleTime" BO_ 1348 50;
BA_ "GenMsgCycleTime" BO_ 1347 50;
BA_ "GenMsgCycleTime" BO_ 1346 50;
BA_ "GenMsgCycleTime" BO_ 1345 50;
BA_ "GenMsgCycleTime" BO_ 1344 50;
BA_ "GenMsgCycleTime" BO_ 1343 50;
BA_ "GenMsgCycleTime" BO_ 1342 50;
BA_ "GenMsgCycleTime" BO_ 1341 50;
BA_ "GenMsgCycleTime" BO_ 1340 50;
BA_ "GenMsgCycleTime" BO_ 1339 50;
BA_ "GenMsgCycleTime" BO_ 1338 50;
BA_ "GenMsgCycleTime" BO_ 1337 50;
BA_ "GenMsgCycleTime" BO_ 1336 50;
BA_ "GenMsgCycleTime" BO_ 1335 50;
BA_ "GenMsgCycleTime" BO_ 1334 50;
BA_ "GenMsgCycleTime" BO_ 1333 50;
BA_ "GenMsgCycleTime" BO_ 1332 50;
BA_ "GenMsgCycleTime" BO_ 1331 50;
BA_ "GenMsgCycleTime" BO_ 1330 50;
BA_ "GenMsgCycleTime" BO_ 1329 50;
BA_ "GenMsgCycleTime" BO_ 1328 50;
BA_ "GenMsgCycleTime" BO_ 1327 50;
BA_ "GenMsgCycleTime" BO_ 1326 50;
BA_ "GenMsgCycleTime" BO_ 1325 50;
BA_ "GenMsgCycleTime" BO_ 1324 50;
BA_ "GenMsgCycleTime" BO_ 1323 50;
BA_ "GenMsgCycleTime" BO_ 1322 50;
BA_ "GenMsgCycleTime" BO_ 1321 50;
BA_ "GenMsgCycleTime" BO_ 1313 50;
BA_ "GenMsgCycleTime" BO_ 1320 50;
BA_ "GenMsgCycleTime" BO_ 1319 50;
BA_ "GenMsgCycleTime" BO_ 1318 50;
BA_ "GenMsgCycleTime" BO_ 1317 50;
BA_ "GenMsgCycleTime" BO_ 1316 50;
BA_ "GenMsgCycleTime" BO_ 1315 50;
BA_ "GenMsgCycleTime" BO_ 1314 50;
BA_ "GenMsgCycleTime" BO_ 1312 50;
BA_ "GenMsgCycleTime" BO_ 1311 50;
BA_ "GenMsgCycleTime" BO_ 1310 50;
BA_ "GenMsgCycleTime" BO_ 1309 50;
BA_ "GenMsgCycleTime" BO_ 1308 50;
BA_ "GenMsgCycleTime" BO_ 1307 50;
BA_ "GenMsgCycleTime" BO_ 1306 50;
BA_ "GenMsgCycleTime" BO_ 1305 50;
BA_ "GenMsgCycleTime" BO_ 1304 50;
BA_ "GenMsgCycleTime" BO_ 1303 50;
BA_ "GenMsgCycleTime" BO_ 1302 50;
BA_ "GenMsgCycleTime" BO_ 1301 50;
BA_ "GenMsgCycleTime" BO_ 1300 50;
BA_ "GenMsgCycleTime" BO_ 1299 50;
BA_ "GenMsgCycleTime" BO_ 1298 50;
BA_ "GenMsgCycleTime" BO_ 1297 50;
BA_ "GenMsgCycleTime" BO_ 1296 50;
BA_ "GenMsgCycleTime" BO_ 1295 50;
BA_ "GenMsgCycleTime" BO_ 1294 50;
BA_ "GenMsgCycleTime" BO_ 1293 50;
BA_ "GenMsgCycleTime" BO_ 1292 50;
BA_ "GenMsgCycleTime" BO_ 1291 50;
BA_ "GenMsgCycleTime" BO_ 1290 50;
BA_ "GenMsgCycleTime" BO_ 1289 50;
BA_ "GenMsgCycleTime" BO_ 1288 50;
BA_ "GenMsgCycleTime" BO_ 1287 50;
BA_ "GenMsgCycleTime" BO_ 1286 50;
BA_ "GenMsgCycleTime" BO_ 1284 50;
BA_ "GenMsgCycleTime" BO_ 1285 50;
BA_ "GenMsgCycleTime" BO_ 1283 50;
BA_ "GenMsgCycleTime" BO_ 1282 50;
BA_ "GenMsgCycleTime" BO_ 1281 50;
BA_ "GenMsgCycleTime" BO_ 1827 50;
BA_ "GenMsgCycleTime" BO_ 1826 50;
BA_ "GenMsgCycleTime" BO_ 1825 50;
BA_ "GenMsgCycleTime" BO_ 1824 50;
BA_ "GenMsgCycleTime" BO_ 1556 50;
BA_ "GenMsgCycleTime" BO_ 1555 50;
BA_ "GenMsgCycleTime" BO_ 1554 50;
BA_ "GenMsgCycleTime" BO_ 1553 50;
BA_ "GenMsgCycleTime" BO_ 1552 50;
BA_ "GenMsgCycleTime" BO_ 1580 50;
BA_ "GenMsgCycleTime" BO_ 1579 50;
BA_ "GenMsgCycleTime" BO_ 1578 50;
BA_ "GenMsgCycleTime" BO_ 1577 50;
BA_ "GenMsgCycleTime" BO_ 1576 50;
BA_ "GenMsgCycleTime" BO_ 1575 50;
BA_ "GenMsgCycleTime" BO_ 1574 50;
BA_ "GenMsgCycleTime" BO_ 1573 50;
BA_ "GenMsgCycleTime" BO_ 1572 50;
BA_ "GenMsgCycleTime" BO_ 1571 50;
BA_ "GenMsgCycleTime" BO_ 1570 50;
BA_ "GenMsgCycleTime" BO_ 1569 50;
BA_ "GenMsgCycleTime" BO_ 1568 50;
BA_ "GenMsgCycleTime" BO_ 1549 50;
BA_ "GenMsgCycleTime" BO_ 1548 50;
BA_ "GenMsgCycleTime" BO_ 1547 50;
BA_ "GenMsgCycleTime" BO_ 1546 50;
BA_ "GenMsgCycleTime" BO_ 1545 50;
BA_ "GenMsgCycleTime" BO_ 1544 50;
BA_ "GenMsgCycleTime" BO_ 1543 50;
BA_ "GenMsgCycleTime" BO_ 1542 50;
BA_ "GenMsgCycleTime" BO_ 1541 50;
BA_ "GenMsgCycleTime" BO_ 1540 50;
BA_ "GenMsgCycleTime" BO_ 1539 50;
BA_ "GenMsgCycleTime" BO_ 1538 50;
BA_ "GenMsgCycleTime" BO_ 1537 50;
BA_ "GenMsgCycleTime" BO_ 1536 50;
BA_ "GenMsgCycleTime" BO_ 1586 20;
BA_ "GenMsgCycleTime" BO_ 1585 20;
BA_ "GenMsgCycleTime" BO_ 1584 100;
BA_ "GenMsgCycleTime" BO_ 1800 100;
BA_ "GenMsgCycleTime" BO_ 1799 100;
BA_ "GenMsgCycleTime" BO_ 1798 100;
BA_ "GenMsgCycleTime" BO_ 1797 100;
BA_ "GenMsgCycleTime" BO_ 1796 100;
BA_ "GenMsgCycleTime" BO_ 1795 100;
BA_ "GenMsgCycleTime" BO_ 1809 100;
BA_ "GenMsgCycleTime" BO_ 1794 100;
BA_ "GenMsgCycleTime" BO_ 1808 100;
BA_ "GenMsgCycleTime" BO_ 1792 100;
BA_ "GenMsgCycleTime" BO_ 1027 50;
BA_ "GenMsgCycleTime" BO_ 1026 50;
BA_ "GenMsgCycleTime" BO_ 1025 50;
BA_ "GenMsgCycleTime" BO_ 1024 50;
VAL_ 3221225472 AVM_Status_Flag 3 "reserved" 2 "abnormal" 1 "normal" 0 "idle" ;
VAL_ 3221225472 AVM_Show_Flag 3 "reserved" 2 "hide" 1 "show" 0 "unknown" ;
VAL_ 3221225472 USS_RR_RRM_Dis_Valid 1 "valid" 0 "invalid" ;
VAL_ 3221225472 USS_RRM_RR_Dis_Valid 1 "valid" 0 "invalid" ;
VAL_ 3221225472 USS_RRM_RLM_Dis_Valid 1 "valid" 0 "invalid" ;
VAL_ 3221225472 USS_RLM_RRM_Dis_Valid 1 "valid" 0 "invalid" ;
VAL_ 3221225472 USS_RLM_RL_Dis_Valid 1 "valid" 0 "invalid" ;
VAL_ 3221225472 USS_RL_RLM_Dis_Valid 1 "valid" 0 "invalid" ;
VAL_ 776 uss8_TR 2 " value '0x2'  R" 1 "value '0x1'  T" 0 "value '0x0'  off " ;
VAL_ 775 uss7_TR 2 " value '0x2'  R" 1 "value '0x1'  T" 0 "value '0x0'  off " ;
VAL_ 774 uss6_TR 2 " value '0x2'  R" 1 "value '0x1'  T" 0 "value '0x0'  off " ;
VAL_ 773 uss5_TR 2 " value '0x2'  R" 1 "value '0x1'  T" 0 "value '0x0'  off " ;
VAL_ 772 uss4_TR 2 " value '0x2' R" 1 "value '0x1'  T" 0 "value '0x0'  off " ;
VAL_ 771 uss3_TR 2 " value '0x2'  R" 1 "value '0x1'  T" 0 "value '0x0'  off " ;
VAL_ 770 uss2_TR 2 " value '0x2'  R" 1 "value '0x1'  T" 0 "value '0x0'  off " ;
VAL_ 769 uss1_TR 2 " value '0x2'  R" 1 "value '0x1'  T" 0 "value '0x0'  off " ;
VAL_ 1827 V_LANELINE_Valid 1 "valid" 0 "invalid" ;
VAL_ 1827 V_LANELINE_Type 9 "reserved" 8 "fence" 7 "curb" 6 "solid-dot" 5 "dot-solid" 4 "double solid" 3 "double dot" 2 "solid" 1 "dot" 0 "unknown" ;
VAL_ 1827 V_LANELINE_COLOR 3 "blue" 2 "yellow" 1 "white" 0 "unknown" ;
VAL_ 1827 V_LANELINE_ASSIGN 3 "right lane" 2 "left lane" 1 "host lane" 0 "unknown" ;
VAL_ 1825 V_OBSTACLE_TYPE 9 "reserved" 8 "uncertain_VCL" 7 "animal" 6 "general object" 5 "pedestrian" 4 "bicycle" 3 "motorbike" 2 "truck" 1 "car" 0 "unfilled" ;
VAL_ 1825 V_OBSTACLE_MotionStatus 6 "reserved" 5 "moving slowly" 4 "stopped" 3 "stationary" 2 "moving" 1 "unknown" 0 "invalid" ;
VAL_ 1825 V_OBSTACLE_MotionDirection 14 "reserved" 13 "oncomming" 12 "preceeding" 11 "moving" 10 "RTAP" 9 "LTAP" 8 "crossing" 7 "moving out" 6 "moving in" 5 "close cut in" 4 "passing out" 3 "passing in" 2 "passing" 1 "undefined" 0 "unfilled" ;
VAL_ 1825 V_OBSTACLE_LaneAssign 7 "reserved" 6 "right-right lane" 5 "left-left lane" 4 "right lane" 3 "left lane" 2 "host lane" 1 "unknown" 0 "invalid" ;
VAL_ 1825 V_OBSTACLE_SRC 7 "reserved" 6 "fusion" 5 "rear view" 4 "surround view" 3 "side view" 2 "front view" 1 "unknown" 0 "invalid" ;
VAL_ 1824 V_LDW_FLAG 3 "reserved" 2 "right departure warning" 1 "left departure warning" 0 "none" ;
VAL_ 1824 V_FCW_FLAG 3 "reserved" 2 "emergency-warning" 1 "pre-warning" 0 "none" ;
VAL_ 1824 V_AEB_FLAG 3 "reserved" 2 "emergency-braking" 1 "pre-braking" 0 "none" ;
VAL_ 1824 V_SV_MODULE_STS 3 "reserved" 2 "abnormal" 1 "normal" 0 "idle" ;
VAL_ 1824 V_SRV_MODULE_STS 3 "reserved" 2 "abnormal" 1 "normal" 0 "idle" ;
VAL_ 1824 V_RV_MODULE_STS 3 "reserved" 2 "abnormal" 1 "normal" 0 "idle" ;
VAL_ 1824 V_FV_MODULE_STS 3 "reserved" 2 "abnormal" 1 "normal" 0 "idle" ;
VAL_ 1556 P_OBJ5_Valid 1 "valid" 0 "invalid" ;
VAL_ 1556 P_OBJ5_TYPE 15 "水马" 14 "施工围栏" 13 "圆桶" 12 "防撞柱" 11 "三脚架" 10 "锥形桶" 9 "禁停牌" 8 "地锁关" 7 "地锁开" 6 "行人" 5 "两轮车
" 4 "三轮车" 3 "公交车" 2 "大卡车" 1 "小汽车" 0 "unfilled" ;
VAL_ 1555 P_OBJ4_Valid 1 "valid" 0 "invalid" ;
VAL_ 1555 P_OBJ4_TYPE 15 "水马" 14 "施工围栏" 13 "圆桶" 12 "防撞柱" 11 "三脚架" 10 "锥形桶" 9 "禁停牌" 8 "地锁关" 7 "地锁开" 6 "行人" 5 "两轮车
" 4 "三轮车" 3 "公交车" 2 "大卡车" 1 "小汽车" 0 "unfilled" ;
VAL_ 1554 P_OBJ3_Valid 1 "valid" 0 "invalid" ;
VAL_ 1554 P_OBJ3_TYPE 15 "水马" 14 "施工围栏" 13 "圆桶" 12 "防撞柱" 11 "三脚架" 10 "锥形桶" 9 "禁停牌" 8 "地锁关" 7 "地锁开" 6 "行人" 5 "两轮车
" 4 "三轮车" 3 "公交车" 2 "大卡车" 1 "小汽车" 0 "unfilled" ;
VAL_ 1553 P_OBJ2_Valid 1 "valid" 0 "invalid" ;
VAL_ 1553 P_OBJ2_TYPE 15 "水马" 14 "施工围栏" 13 "圆桶" 12 "防撞柱" 11 "三脚架" 10 "锥形桶" 9 "禁停牌" 8 "地锁关" 7 "地锁开" 6 "行人" 5 "两轮车
" 4 "三轮车" 3 "公交车" 2 "大卡车" 1 "小汽车" 0 "unfilled" ;
VAL_ 1552 P_OBJ1_TYPE 15 "水马" 14 "施工围栏" 13 "圆桶" 12 "防撞柱" 11 "三脚架" 10 "锥形桶" 9 "禁停牌" 8 "地锁关" 7 "地锁开" 6 "行人" 5 "两轮车
" 4 "三轮车" 3 "公交车" 2 "大卡车" 1 "小汽车" 0 "unfilled" ;
VAL_ 1552 P_OBJ1_Valid 1 "valid" 0 "invalid" ;
VAL_ 1580 P_AVM_OnOff_Flag 3 "reserved" 2 "off" 1 "on" 0 "none" ;
VAL_ 1580 AVM_Mode_Flag 15 "Automatic" 14 "3D Rear Right View" 13 "3D Front Right View" 12 "3D Rear Left View" 11 "3D Front Left View" 10 "3D Right View" 9 "3D Left View" 8 "3D Rear View" 7 "3D Front View" 6 "2D Right Back View" 5 "2D Left Back View" 4 "2D Right View" 3 "2D Left View" 2 "2D Rear View" 1 "2D Front View" 0 "invalid" ;
VAL_ 1580 P_FS_Valid13 1 "valid" 0 "invalid" ;
VAL_ 1579 P_FS_Valid12 1 "valid" 0 "invalid" ;
VAL_ 1578 P_FS_Valid11 1 "valid" 0 "invalid" ;
VAL_ 1577 P_FS_Valid10 1 "valid" 0 "invalid" ;
VAL_ 1576 P_FS_Valid9 1 "valid" 0 "invalid" ;
VAL_ 1575 P_FS_Valid8 1 "valid" 0 "invalid" ;
VAL_ 1574 P_FS_Valid7 1 "valid" 0 "invalid" ;
VAL_ 1573 P_FS_Valid6 1 "valid" 0 "invalid" ;
VAL_ 1572 P_FS_Valid5 1 "valid" 0 "invalid" ;
VAL_ 1571 P_FS_Valid4 1 "valid" 0 "invalid" ;
VAL_ 1570 P_FS_Valid3 1 "valid" 0 "invalid" ;
VAL_ 1569 P_FS_Valid2 1 "valid" 0 "invalid" ;
VAL_ 1568 P_FS_Valid1 1 "valid" 0 "invalid" ;
VAL_ 1549 P_APA_Slot6_Conti1 1 "valid" 0 "invalid" ;
VAL_ 1548 P_APA_Slot6_Type 5 "diagonal 60" 4 "diagonal 45" 3 "diagonal 30" 2 "vertical" 1 "horizontal" 0 "invalid" ;
VAL_ 1548 P_APA_Slot6_Valid 1 "valid" 0 "invalid" ;
VAL_ 1547 P_APA_Slot5_Conti1 1 "valid" 0 "invalid" ;
VAL_ 1546 P_APA_Slot5_Type 5 "diagonal 60" 4 "diagonal 45" 3 "diagonal 30" 2 "vertical" 1 "horizontal" 0 "invalid" ;
VAL_ 1546 P_APA_Slot5_Valid 1 "valid" 0 "invalid" ;
VAL_ 1545 P_APA_Slot4_Conti1 1 "valid" 0 "invalid" ;
VAL_ 1544 P_APA_Slot4_Type 5 "diagonal 60" 4 "diagonal 45" 3 "diagonal 30" 2 "vertical" 1 "horizontal" 0 "invalid" ;
VAL_ 1544 P_APA_Slot4_Valid 1 "valid" 0 "invalid" ;
VAL_ 1543 P_APA_Slot3_Conti1 1 "valid" 0 "invalid" ;
VAL_ 1542 P_APA_Slot3_Type 5 "diagonal 60" 4 "diagonal 45" 3 "diagonal 30" 2 "vertical" 1 "horizontal" 0 "invalid" ;
VAL_ 1542 P_APA_Slot3_Valid 1 "valid" 0 "invalid" ;
VAL_ 1541 P_APA_Slot2_Conti1 1 "valid" 0 "invalid" ;
VAL_ 1540 P_APA_Slot2_Type 5 "diagonal 60" 4 "diagonal 45" 3 "diagonal 30" 2 "vertical" 1 "horizontal" 0 "invalid" ;
VAL_ 1540 P_APA_Slot2_Valid 1 "valid" 0 "invalid" ;
VAL_ 1539 P_APA_Slot1_Conti3 1 "valid" 0 "invalid" ;
VAL_ 1538 P_APA_Slot1_Conti2 1 "valid" 0 "invalid" ;
VAL_ 1537 P_APA_Slot1_Conti1 1 "valid" 0 "invalid" ;
VAL_ 1536 P_APA_Slot1_Type 5 "diagonal 60" 4 "diagonal 45" 3 "diagonal 30" 2 "vertical" 1 "horizontal" 0 "invalid" ;
VAL_ 1536 P_APA_Slot1_Valid 1 "valid" 0 "invalid" ;
VAL_ 1586 P_Sync_Valid 1 "valid" 0 "invalid" ;
VAL_ 1585 P_Vehicle_Gear 4 "reverse" 3 "forward" 2 "neutral" 1 "parked" 0 "invalid" ;
VAL_ 1584 P_AVM_OnOff 3 "reserved" 2 "off" 1 "on" 0 "none" ;
VAL_ 1584 P_APA_OnOff 3 "reserved" 2 "off" 1 "on" 0 "none" ;
VAL_ 1584 P_APA_Status 7 "suspended" 6 "terminated" 5 "failure" 4 "completed" 3 "guidance active" 2 "searching" 1 "standby" 0 "off" ;
VAL_ 1584 P_APA_Mode 3 "reserved" 2 "parking out" 1 "parking in" 0 "none" ;
VAL_ 1584 P_AVM_Mode 15 "Automatic" 14 "3D Rear Right View" 13 "3D Front Right View" 12 "3D Rear Left View" 11 "3D Front Left View" 10 "3D Right View" 9 "3D Left View" 8 "3D Rear View" 7 "3D Front View" 6 "2D Right Back View" 5 "2D Left Back View" 4 "2D Right View" 3 "2D Left View" 2 "2D Rear View" 1 "2D Front View" 0 "invalid" ;
VAL_ 1800 APA_Slot6_Type 5 "diagonal 60" 4 "diagonal 45" 3 "diagonal 30" 2 "vertical" 1 "horizontal" 0 "invalid" ;
VAL_ 1800 APA_Slot6_Valid 1 "valid" 0 "invalid" ;
VAL_ 1799 APA_Slot5_Type 5 "diagonal 60" 4 "diagonal 45" 3 "diagonal 30" 2 "vertical" 1 "horizontal" 0 "invalid" ;
VAL_ 1799 APA_Slot5_Valid 1 "valid" 0 "invalid" ;
VAL_ 1798 APA_Slot4_Type 5 "diagonal 60" 4 "diagonal 45" 3 "diagonal 30" 2 "vertical" 1 "horizontal" 0 "invalid" ;
VAL_ 1798 APA_Slot4_Valid 1 "valid" 0 "invalid" ;
VAL_ 1797 APA_Slot3_Type 5 "diagonal 60" 4 "diagonal 45" 3 "diagonal 30" 2 "vertical" 1 "horizontal" 0 "invalid" ;
VAL_ 1797 APA_Slot3_Valid 1 "valid" 0 "invalid" ;
VAL_ 1796 APA_Slot2_Type 5 "diagonal 60" 4 "diagonal 45" 3 "diagonal 30" 2 "vertical" 1 "horizontal" 0 "invalid" ;
VAL_ 1796 APA_Slot2_Valid 1 "valid" 0 "invalid" ;
VAL_ 1795 APA_Slot1_Type 5 "diagonal 60" 4 "diagonal 45" 3 "diagonal 30" 2 "vertical" 1 "horizontal" 0 "invalid" ;
VAL_ 1795 APA_Slot1_Valid 1 "valid" 0 "invalid" ;
VAL_ 1809 APA_SelectedSlot_Type 5 "diagonal 60" 4 "diagonal 45" 3 "diagonal 30" 2 "vertical" 1 "horizontal" 0 "invalid" ;
VAL_ 1809 APA_SelectedSlot_Req 3 "reserved" 2 "created" 1 "selected" 0 "none" ;
VAL_ 1809 APA_Mode_Req 3 "reserved" 2 "parking out" 1 "parking in" 0 "none" ;
VAL_ 1809 APA_OnOff_Req 3 "reserved" 2 "off" 1 "on" 0 "none" ;
VAL_ 1794 APA_Status 7 "suspended" 6 "terminated" 5 "failure" 4 "completed" 3 "guidance active" 2 "searching" 1 "standby" 0 "off" ;
VAL_ 1794 APA_MODE 3 "reserved" 2 "parking out" 1 "parking in" 0 "none" ;
VAL_ 1794 APA_MODULE_STS 3 "reserved" 2 "abnormal" 1 "normal" 0 "idle" ;
VAL_ 1808 AVM_Mode_Req 15 "Automatic" 14 "3D Rear Right View" 13 "3D Front Right View" 12 "3D Rear Left View" 11 "3D Front Left View" 10 "3D Right View" 9 "3D Left View" 8 "3D Rear View" 7 "3D Front View" 6 "2D Right Back View" 5 "2D Left Back View" 4 "2D Right View" 3 "2D Left View" 2 "2D Rear View" 1 "2D Front View" 0 "invalid" ;
VAL_ 1808 AVM_OnOff_Req 3 "reserved" 2 "off" 1 "on" 0 "none" ;
VAL_ 1792 PDC_RRS_Status 3 "far" 2 "middle" 1 "near" 0 "no detected" ;
VAL_ 1792 PDC_RLS_Status 3 "far" 2 "middle" 1 "near" 0 "no detected" ;
VAL_ 1792 PDC_FRS_Status 3 "far" 2 "middle" 1 "near" 0 "no detected" ;
VAL_ 1792 PDC_FLS_Status 3 "far" 2 "middle" 1 "near" 0 "no detected" ;
VAL_ 1792 PDC_RR_Status 3 "far" 2 "middle" 1 "near" 0 "no detected" ;
VAL_ 1792 PDC_RRM_Status 3 "far" 2 "middle" 1 "near" 0 "no detected" ;
VAL_ 1792 PDC_RLM_Status 3 "far" 2 "middle" 1 "near" 0 "no detected" ;
VAL_ 1792 PDC_RL_Status 3 "far" 2 "middle" 1 "near" 0 "no detected" ;
VAL_ 1792 PDC_FR_Status 3 "far" 2 "middle" 1 "near" 0 "no detected" ;
VAL_ 1792 PDC_FRM_Status 3 "far" 2 "middle" 1 "near" 0 "no detected" ;
VAL_ 1792 PDC_FLM_Status 3 "far" 2 "middle" 1 "near" 0 "no detected" ;
VAL_ 1792 PDC_FL_Status 3 "far" 2 "middle" 1 "near" 0 "no detected" ;
VAL_ 1792 PDC_Sys_Status 3 "reserved" 2 "abnormal" 1 "normal" 0 "idle" ;
VAL_ 1027 USS_RR_RRM_Dis_Valid 1 "valid" 0 "invalid" ;
VAL_ 1027 USS_RRM_RR_Dis_Valid 1 "valid" 0 "invalid" ;
VAL_ 1027 USS_RRM_RLM_Dis_Valid 1 "valid" 0 "invalid" ;
VAL_ 1027 USS_RLM_RRM_Dis_Valid 1 "valid" 0 "invalid" ;
VAL_ 1027 USS_RLM_RL_Dis_Valid 1 "valid" 0 "invalid" ;
VAL_ 1027 USS_RL_RLM_Dis_Valid 1 "valid" 0 "invalid" ;
VAL_ 1026 USS_FR_FRM_Dis_Valid 1 "valid" 0 "invalid" ;
VAL_ 1026 USS_FRM_FR_Dis_Valid 1 "valid" 0 "invalid" ;
VAL_ 1026 USS_FRM_FLM_Dis_Valid 1 "valid" 0 "invalid" ;
VAL_ 1026 USS_FLM_FRM_Dis_Valid 1 "valid" 0 "invalid" ;
VAL_ 1026 USS_FLM_FL_Dis_Valid 1 "valid" 0 "invalid" ;
VAL_ 1026 USS_FL_FLM_Dis_Valid 1 "valid" 0 "invalid" ;
VAL_ 1025 USS_RRS_Dis_Valid 1 "valid" 0 "invalid" ;
VAL_ 1025 USS_RLS_Dis_Valid 1 "valid" 0 "invalid" ;
VAL_ 1025 USS_RR_Dis_Valid 1 "valid" 0 "invalid" ;
VAL_ 1025 USS_RRM_Dis_Valid 1 "valid" 0 "invalid" ;
VAL_ 1025 USS_RLM_Dis_Valid 1 "valid" 0 "invalid" ;
VAL_ 1025 USS_RL_Dis_Valid 1 "valid" 0 "invalid" ;
VAL_ 1024 USS_FLS_Dis_Valid 1 "valid" 0 "invalid" ;
VAL_ 1024 USS_FR_Dis_Valid 1 "valid" 0 "invalid" ;
VAL_ 1024 USS_FRS_Dis_Valid 1 "valid" 0 "invalid" ;
VAL_ 1024 USS_FRM_Dis_Valid 1 "valid" 0 "invalid" ;
VAL_ 1024 USS_FLM_Dis_Valid 1 "valid" 0 "invalid" ;
VAL_ 1024 USS_FL_Dis_Valid 1 "valid" 0 "invalid" ;
